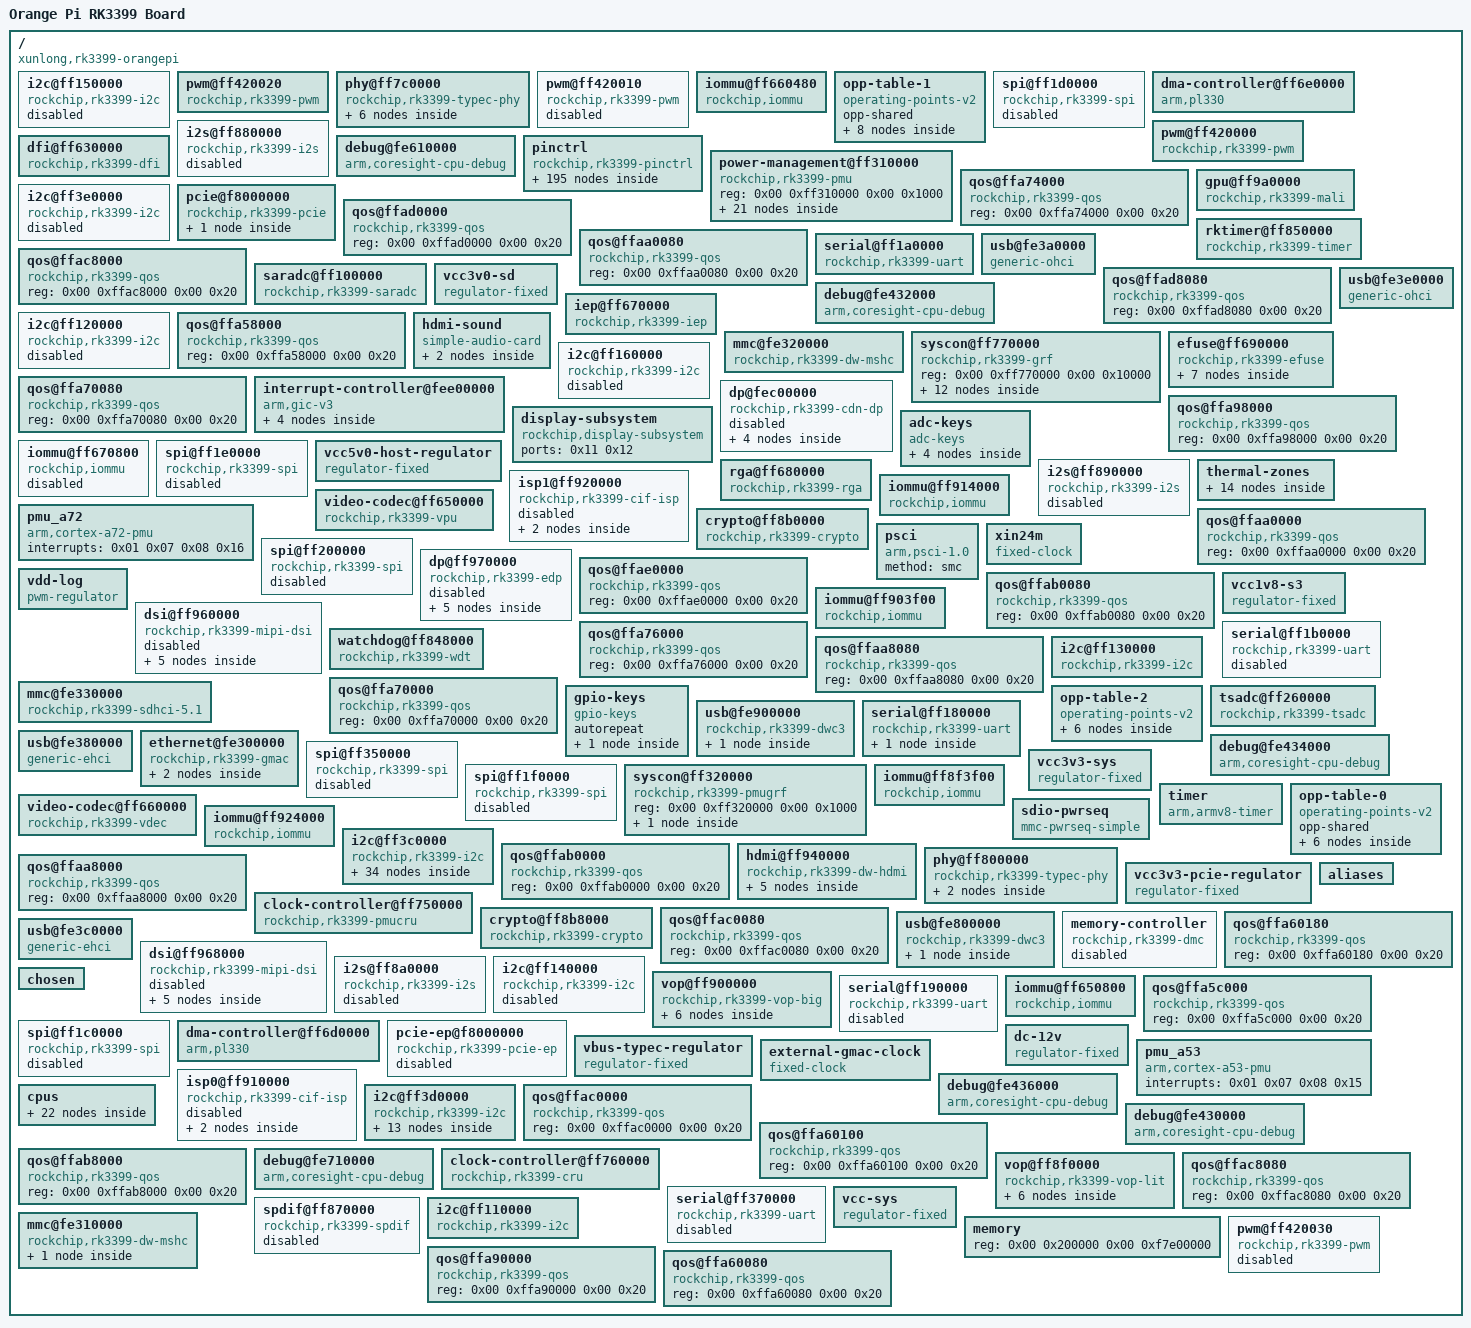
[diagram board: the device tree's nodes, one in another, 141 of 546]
/dts-v1/;

/ {
	#address-cells = <0x02>;
	model = "Orange Pi RK3399 Board";
	serial-number = "e1e9646c4d83d120";
	#size-cells = <0x02>;
	interrupt-parent = <0x01>;
	compatible = "xunlong,rk3399-orangepi\0rockchip,rk3399";

	i2c@ff150000 {
		pinctrl-names = "default";
		#address-cells = <0x01>;
		pinctrl-0 = <0x43>;
		clock-names = "i2c\0pclk";
		assigned-clocks = <0x08 0x45>;
		assigned-clock-rates = <0xbebc200>;
		interrupts = <0x00 0x25 0x04 0x00>;
		clocks = <0x08 0x45 0x08 0x159>;
		#size-cells = <0x00>;
		compatible = "rockchip,rk3399-i2c";
		status = "disabled";
		reg = <0x00 0xff150000 0x00 0x1000>;
		phandle = <0xf0>;
	};

	pwm@ff420020 {
		pinctrl-names = "default";
		pinctrl-0 = <0x9c>;
		clocks = <0x84 0x1e>;
		#pwm-cells = <0x03>;
		compatible = "rockchip,rk3399-pwm\0rockchip,rk3288-pwm";
		status = "okay";
		reg = <0x00 0xff420020 0x00 0x10>;
		phandle = <0xd9>;
	};

	phy@ff7c0000 {
		power-domains = <0x1c 0x08>;
		clock-names = "tcpdcore\0tcpdphy-ref";
		assigned-clocks = <0x08 0x7e>;
		assigned-clock-rates = <0x2faf080>;
		resets = <0x08 0x95 0x08 0x94 0x08 0x14c>;
		clocks = <0x08 0x7e 0x08 0x7d>;
		compatible = "rockchip,rk3399-typec-phy";
		status = "okay";
		rockchip,grf = <0x1d>;
		reg = <0x00 0xff7c0000 0x00 0x40000>;
		phandle = <0x124>;
		reset-names = "uphy\0uphy-pipe\0uphy-tcphy";

		dp-port {
			#phy-cells = <0x00>;
			phandle = <0x3a>;

			port {

				endpoint {
					remote-endpoint = <0xa6>;
					phandle = <0x98>;
				};
			};
		};

		usb3-port {
			#phy-cells = <0x00>;
			phandle = <0x37>;

			port {

				endpoint {
					remote-endpoint = <0xa7>;
					phandle = <0x97>;
				};
			};
		};
	};

	pwm@ff420010 {
		pinctrl-names = "default";
		pinctrl-0 = <0x9b>;
		clocks = <0x84 0x1e>;
		#pwm-cells = <0x03>;
		compatible = "rockchip,rk3399-pwm\0rockchip,rk3288-pwm";
		status = "disabled";
		reg = <0x00 0xff420010 0x00 0x10>;
		phandle = <0x115>;
	};

	iommu@ff660480 {
		power-domains = <0x1c 0x20>;
		clock-names = "aclk\0iface";
		interrupts = <0x00 0x75 0x04 0x00>;
		clocks = <0x08 0xed 0x08 0x1ec>;
		#iommu-cells = <0x00>;
		compatible = "rockchip,iommu";
		reg = <0x00 0xff660480 0x00 0x40 0x00 0xff6604c0 0x00 0x40>;
		phandle = <0x9f>;
	};

	opp-table-1 {
		opp-shared;
		compatible = "operating-points-v2";
		phandle = <0x0f>;

		opp04 {
			opp-microvolt = <0xe7ef0 0xe7ef0 0x1312d0>;
			opp-hz = <0x00 0x47868c00>;
		};

		opp02 {
			opp-microvolt = <0xc96a8 0xc96a8 0x1312d0>;
			opp-hz = <0x00 0x30a32c00>;
		};

		opp00 {
			opp-microvolt = <0xc96a8 0xc96a8 0x1312d0>;
			opp-hz = <0x00 0x18519600>;
			clock-latency-ns = <0x9c40>;
		};

		opp07 {
			opp-microvolt = <0x124f80 0x124f80 0x1312d0>;
			opp-hz = <0x00 0x6b49d200>;
		};

		opp05 {
			opp-microvolt = <0xfa3e8 0xfa3e8 0x1312d0>;
			opp-hz = <0x00 0x54667200>;
		};

		opp03 {
			opp-microvolt = <0xd59f8 0xd59f8 0x1312d0>;
			opp-hz = <0x00 0x3c14dc00>;
		};

		opp01 {
			opp-microvolt = <0xc96a8 0xc96a8 0x1312d0>;
			opp-hz = <0x00 0x23c34600>;
		};

		opp06 {
			opp-microvolt = <0x10c8e0 0x10c8e0 0x1312d0>;
			opp-hz = <0x00 0x5fd82200>;
		};
	};

	spi@ff1d0000 {
		pinctrl-names = "default";
		#address-cells = <0x01>;
		pinctrl-0 = <0x56 0x57 0x58 0x59>;
		clock-names = "spiclk\0apb_pclk";
		interrupts = <0x00 0x35 0x04 0x00>;
		clocks = <0x08 0x48 0x08 0x15c>;
		#size-cells = <0x00>;
		dma-names = "tx\0rx";
		compatible = "rockchip,rk3399-spi\0rockchip,rk3066-spi";
		status = "disabled";
		reg = <0x00 0xff1d0000 0x00 0x1000>;
		phandle = <0xf7>;
		dmas = <0x51 0x0c 0x51 0x0d>;
	};

	dma-controller@ff6e0000 {
		clock-names = "apb_pclk";
		interrupts = <0x00 0x07 0x04 0x00 0x00 0x08 0x04 0x00>;
		clocks = <0x08 0xd4>;
		arm,pl330-periph-burst;
		compatible = "arm,pl330\0arm,primecell";
		reg = <0x00 0xff6e0000 0x00 0x4000>;
		phandle = <0x51>;
		#dma-cells = <0x01>;
	};

	i2s@ff880000 {
		power-domains = <0x1c 0x1c>;
		pinctrl-names = "bclk_on\0bclk_off";
		pinctrl-0 = <0xa9>;
		clock-names = "i2s_clk\0i2s_hclk";
		interrupts = <0x00 0x27 0x04 0x00>;
		clocks = <0x08 0x56 0x08 0x1d4>;
		dma-names = "tx\0rx";
		#sound-dai-cells = <0x00>;
		compatible = "rockchip,rk3399-i2s\0rockchip,rk3066-i2s";
		pinctrl-1 = <0xaa>;
		status = "disabled";
		rockchip,grf = <0x1d>;
		reg = <0x00 0xff880000 0x00 0x1000>;
		phandle = <0x128>;
		dmas = <0x62 0x00 0x62 0x01>;
	};

	pwm@ff420000 {
		pinctrl-names = "default";
		pinctrl-0 = <0x9a>;
		clocks = <0x84 0x1e>;
		#pwm-cells = <0x03>;
		compatible = "rockchip,rk3399-pwm\0rockchip,rk3288-pwm";
		status = "okay";
		reg = <0x00 0xff420000 0x00 0x10>;
		phandle = <0x114>;
	};

	debug@fe610000 {
		clock-names = "apb_pclk";
		clocks = <0x08 0x14c>;
		cpu = <0x06>;
		compatible = "arm,coresight-cpu-debug\0arm,primecell";
		reg = <0x00 0xfe610000 0x00 0x1000>;
	};

	pinctrl {
		#address-cells = <0x02>;
		#size-cells = <0x02>;
		compatible = "rockchip,rk3399-pinctrl";
		rockchip,pmu = <0x13>;
		ranges;
		rockchip,grf = <0x1d>;
		phandle = <0x139>;

		i2c3 {

			i2c3-xfer {
				rockchip,pins = <0x04 0x11 0x01 0xca 0x04 0x10 0x01 0xca>;
				phandle = <0x41>;
			};
		};

		buttons {

			pwr-btn {
				rockchip,pins = <0x00 0x05 0x00 0xcc>;
				phandle = <0xd1>;
			};
		};

		mpu6500 {

			gsensor-int-l {
				rockchip,pins = <0x01 0x16 0x00 0xca>;
				phandle = <0x90>;
			};
		};

		clock {

			clk-32k {
				rockchip,pins = <0x00 0x00 0x02 0xca>;
				phandle = <0x149>;
			};
		};

		spi2 {

			spi2-clk {
				rockchip,pins = <0x02 0x0b 0x01 0xcc>;
				phandle = <0x5a>;
			};

			spi2-cs0 {
				rockchip,pins = <0x02 0x0c 0x01 0xcc>;
				phandle = <0x5d>;
			};

			spi2-tx {
				rockchip,pins = <0x02 0x0a 0x01 0xcc>;
				phandle = <0x5b>;
			};

			spi2-rx {
				rockchip,pins = <0x02 0x09 0x01 0xcc>;
				phandle = <0x5c>;
			};
		};

		pcfg-pull-none-12ma {
			drive-strength = <0x0c>;
			bias-disable;
			phandle = <0xcd>;
		};

		pcfg-pull-up-20ma {
			drive-strength = <0x14>;
			phandle = <0x13e>;
			bias-pull-up;
		};

		gpio@ff720000 {
			gpio-controller;
			interrupts = <0x00 0x0e 0x04 0x00>;
			clocks = <0x84 0x17>;
			compatible = "rockchip,gpio-bank";
			#interrupt-cells = <0x02>;
			reg = <0x00 0xff720000 0x00 0x100>;
			phandle = <0x29>;
			#gpio-cells = <0x02>;
			interrupt-controller;
		};

		pcfg-input-pull-up {
			phandle = <0x147>;
			bias-pull-up;
			input-enable;
		};

		i2s1 {

			i2s1-2ch-bus-bclk-off {
				rockchip,pins = <0x04 0x03 0x00 0xca 0x04 0x04 0x01 0xca 0x04 0x05 0x01 0xca 0x04 0x06 0x01 0xca 0x04 0x07 0x01 0xca>;
				phandle = <0x14f>;
			};

			i2s1-2ch-bus {
				rockchip,pins = <0x04 0x03 0x01 0xca 0x04 0x04 0x01 0xca 0x04 0x05 0x01 0xca 0x04 0x06 0x01 0xca 0x04 0x07 0x01 0xca>;
				phandle = <0xab>;
			};
		};

		i2c1 {

			i2c1-xfer {
				rockchip,pins = <0x04 0x02 0x01 0xca 0x04 0x01 0x01 0xca>;
				phandle = <0x3f>;
			};
		};

		gmac {

			rmii-pins {
				rockchip,pins = <0x03 0x0d 0x01 0xca 0x03 0x0c 0x01 0xcb 0x03 0x0b 0x01 0xca 0x03 0x0a 0x01 0xca 0x03 0x09 0x01 0xca 0x03 0x08 0x01 0xca 0x03 0x07 0x01 0xca 0x03 0x06 0x01 0xca 0x03 0x05 0x01 0xcb 0x03 0x04 0x01 0xcb>;
				phandle = <0x14c>;
			};

			phy-rstb {
				rockchip,pins = <0x03 0x0f 0x00 0xca>;
				phandle = <0x23>;
			};

			phy-intb {
				rockchip,pins = <0x03 0x0a 0x00 0xcc>;
				phandle = <0x22>;
			};

			rgmii-pins {
				rockchip,pins = <0x03 0x11 0x01 0xcb 0x03 0x0e 0x01 0xca 0x03 0x0d 0x01 0xca 0x03 0x0c 0x01 0xcb 0x03 0x0b 0x01 0xca 0x03 0x09 0x01 0xca 0x03 0x08 0x01 0xca 0x03 0x07 0x01 0xca 0x03 0x06 0x01 0xca 0x03 0x05 0x01 0xcb 0x03 0x04 0x01 0xcb 0x03 0x03 0x01 0xca 0x03 0x02 0x01 0xca 0x03 0x01 0x01 0xcb 0x03 0x00 0x01 0xcb>;
				phandle = <0x21>;
			};
		};

		spi0 {

			spi0-tx {
				rockchip,pins = <0x03 0x05 0x02 0xcc>;
				phandle = <0x53>;
			};

			spi0-rx {
				rockchip,pins = <0x03 0x04 0x02 0xcc>;
				phandle = <0x54>;
			};

			spi0-cs1 {
				rockchip,pins = <0x03 0x08 0x02 0xcc>;
				phandle = <0x15c>;
			};

			spi0-clk {
				rockchip,pins = <0x03 0x06 0x02 0xcc>;
				phandle = <0x52>;
			};

			spi0-cs0 {
				rockchip,pins = <0x03 0x07 0x02 0xcc>;
				phandle = <0x55>;
			};
		};

		pcfg-pull-down-4ma {
			drive-strength = <0x04>;
			bias-pull-down;
			phandle = <0x13f>;
		};

		wifi {

			wifi-host-wake-l {
				rockchip,pins = <0x00 0x03 0x00 0xca>;
				phandle = <0x2a>;
			};
		};

		cm32181 {

			light-int-l {
				rockchip,pins = <0x04 0x18 0x00 0xca>;
				phandle = <0x93>;
			};
		};

		pcfg-pull-down {
			bias-pull-down;
			phandle = <0xcf>;
		};

		uart4 {

			uart4-xfer {
				rockchip,pins = <0x01 0x07 0x01 0xcc 0x01 0x08 0x01 0xca>;
				phandle = <0x89>;
			};
		};

		pcfg-pull-none-18ma {
			drive-strength = <0x12>;
			bias-disable;
			phandle = <0x13a>;
		};

		i2c8 {

			i2c8-xfer {
				rockchip,pins = <0x01 0x15 0x01 0xca 0x01 0x14 0x01 0xca>;
				phandle = <0x99>;
			};
		};

		pcfg-input-pull-down {
			bias-pull-down;
			phandle = <0x148>;
			input-enable;
		};

		pcfg-pull-none-20ma {
			drive-strength = <0x14>;
			bias-disable;
			phandle = <0x13b>;
		};

		gpio@ff730000 {
			gpio-controller;
			interrupts = <0x00 0x0f 0x04 0x00>;
			clocks = <0x84 0x18>;
			compatible = "rockchip,gpio-bank";
			#interrupt-cells = <0x02>;
			reg = <0x00 0xff730000 0x00 0x100>;
			phandle = <0x8b>;
			#gpio-cells = <0x02>;
			interrupt-controller;
		};

		i2c6 {

			i2c6-xfer {
				rockchip,pins = <0x02 0x0a 0x02 0xca 0x02 0x09 0x02 0xca>;
				phandle = <0x43>;
			};
		};

		uarthdcp {

			uarthdcp-xfer {
				rockchip,pins = <0x04 0x15 0x02 0xcc 0x04 0x16 0x02 0xca>;
				phandle = <0x164>;
			};
		};

		pwm1 {

			pwm1-pin {
				rockchip,pins = <0x04 0x16 0x01 0xca>;
				phandle = <0x9b>;
			};

			pwm1-pin-pull-down {
				rockchip,pins = <0x04 0x16 0x01 0xcf>;
				phandle = <0x168>;
			};
		};

		uart2b {

			uart2b-xfer {
				rockchip,pins = <0x04 0x10 0x02 0xcc 0x04 0x11 0x02 0xca>;
				phandle = <0x161>;
			};
		};

		edp {

			edp-hpd {
				rockchip,pins = <0x04 0x17 0x02 0xca>;
				phandle = <0xc5>;
			};
		};

		spi5 {

			spi5-cs0 {
				rockchip,pins = <0x02 0x17 0x02 0xcc>;
				phandle = <0x66>;
			};

			spi5-tx {
				rockchip,pins = <0x02 0x15 0x02 0xcc>;
				phandle = <0x64>;
			};

			spi5-rx {
				rockchip,pins = <0x02 0x14 0x02 0xcc>;
				phandle = <0x65>;
			};

			spi5-clk {
				rockchip,pins = <0x02 0x16 0x02 0xcc>;
				phandle = <0x63>;
			};
		};

		tsadc {

			otp-pin {
				rockchip,pins = <0x01 0x06 0x00 0xca>;
				phandle = <0x6c>;
			};

			otp-out {
				rockchip,pins = <0x01 0x06 0x01 0xca>;
				phandle = <0x6d>;
			};
		};

		uart0 {

			uart0-cts {
				rockchip,pins = <0x02 0x12 0x01 0xca>;
				phandle = <0x46>;
			};

			uart0-rts {
				rockchip,pins = <0x02 0x13 0x01 0xca>;
				phandle = <0x47>;
			};

			uart0-xfer {
				rockchip,pins = <0x02 0x10 0x01 0xcc 0x02 0x11 0x01 0xca>;
				phandle = <0x45>;
			};
		};

		i2c4 {

			i2c4-xfer {
				rockchip,pins = <0x01 0x0c 0x01 0xca 0x01 0x0b 0x01 0xca>;
				phandle = <0x8f>;
			};
		};

		pcfg-pull-down-12ma {
			drive-strength = <0x0c>;
			bias-pull-down;
			phandle = <0x141>;
		};

		spdif {

			spdif-bus-1 {
				rockchip,pins = <0x03 0x10 0x03 0xca>;
				phandle = <0x15b>;
			};

			spdif-bus {
				rockchip,pins = <0x04 0x15 0x01 0xca>;
				phandle = <0xa8>;
			};
		};

		pcfg-output-high {
			output-high;
			phandle = <0x144>;
		};

		pcie {

			pci-clkreqn-cpm {
				rockchip,pins = <0x02 0x1a 0x00 0xca>;
				phandle = <0x16d>;
			};

			pci-clkreqnb-cpm {
				rockchip,pins = <0x04 0x18 0x00 0xca>;
				phandle = <0x1b>;
			};

			pcie-drv {
				rockchip,pins = <0x00 0x02 0x00 0xca>;
				phandle = <0xd4>;
			};
		};

		sd {

			sdmmc0-pwr-h {
				rockchip,pins = <0x00 0x01 0x00 0xca>;
				phandle = <0xd3>;
			};
		};

		pcfg-pull-up {
			phandle = <0xcc>;
			bias-pull-up;
		};

		spi3 {

			spi3-tx {
				rockchip,pins = <0x01 0x10 0x01 0xcc>;
				phandle = <0x86>;
			};

			spi3-rx {
				rockchip,pins = <0x01 0x0f 0x01 0xcc>;
				phandle = <0x87>;
			};

			spi3-clk {
				rockchip,pins = <0x01 0x11 0x01 0xcc>;
				phandle = <0x85>;
			};

			spi3-cs0 {
				rockchip,pins = <0x01 0x12 0x01 0xcc>;
				phandle = <0x88>;
			};
		};

		fusb302 {

			chg-cc-int-l {
				rockchip,pins = <0x01 0x02 0x00 0xcc>;
				phandle = <0x94>;
			};
		};

		pwm3a {

			pwm3a-pin {
				rockchip,pins = <0x00 0x06 0x01 0xca>;
				phandle = <0x9d>;
			};
		};

		sdio0 {

			sdio0-clk {
				rockchip,pins = <0x02 0x19 0x01 0xca>;
				phandle = <0x28>;
			};

			sdio0-wp {
				rockchip,pins = <0x00 0x03 0x01 0xcc>;
				phandle = <0x154>;
			};

			sdio0-bus4 {
				rockchip,pins = <0x02 0x14 0x01 0xcc 0x02 0x15 0x01 0xcc 0x02 0x16 0x01 0xcc 0x02 0x17 0x01 0xcc>;
				phandle = <0x26>;
			};

			sdmmc-pwr {
				rockchip,pins = <0x00 0x01 0x01 0xcc>;
				phandle = <0x156>;
			};

			sdio0-bkpwr {
				rockchip,pins = <0x02 0x1c 0x01 0xcc>;
				phandle = <0x153>;
			};

			sdio0-cd {
				rockchip,pins = <0x02 0x1a 0x01 0xcc>;
				phandle = <0x151>;
			};

			sdio0-pwr {
				rockchip,pins = <0x02 0x1b 0x01 0xcc>;
				phandle = <0x152>;
			};

			sdio0-int {
				rockchip,pins = <0x00 0x04 0x01 0xcc>;
				phandle = <0x155>;
			};

			sdio0-bus1 {
				rockchip,pins = <0x02 0x14 0x01 0xcc>;
				phandle = <0x150>;
			};

			sdio0-cmd {
				rockchip,pins = <0x02 0x18 0x01 0xcc>;
				phandle = <0x27>;
			};
		};

		pcfg-pull-up-2ma {
			drive-strength = <0x02>;
			phandle = <0x13c>;
			bias-pull-up;
		};

		i2c2 {

			i2c2-xfer {
				rockchip,pins = <0x02 0x01 0x02 0xcd 0x02 0x00 0x02 0xcd>;
				phandle = <0x40>;
			};
		};

		lsm6ds3 {

			gyr-int-l {
				rockchip,pins = <0x01 0x18 0x00 0xca>;
				phandle = <0x91>;
			};
		};

		pmic {

			gpu-sleep {
				rockchip,pins = <0x01 0x0e 0x00 0xcf>;
				phandle = <0x8e>;
			};

			cpu-b-sleep {
				rockchip,pins = <0x01 0x11 0x00 0xcf>;
				phandle = <0x8d>;
			};

			pmic-int-l {
				rockchip,pins = <0x01 0x15 0x00 0xcc>;
				phandle = <0x8c>;
			};
		};

		pcfg-input-enable {
			phandle = <0x146>;
			input-enable;
		};

		pcfg-pull-none {
			bias-disable;
			phandle = <0xca>;
		};

		spi1 {

			spi1-cs0 {
				rockchip,pins = <0x01 0x0a 0x02 0xcc>;
				phandle = <0x59>;
			};

			spi1-clk {
				rockchip,pins = <0x01 0x09 0x02 0xcc>;
				phandle = <0x56>;
			};

			spi1-tx {
				rockchip,pins = <0x01 0x08 0x02 0xcc>;
				phandle = <0x57>;
			};

			spi1-rx {
				rockchip,pins = <0x01 0x07 0x02 0xcc>;
				phandle = <0x58>;
			};
		};

		sdio-pwrseq {

			wifi-reg-on-h {
				rockchip,pins = <0x00 0x0a 0x00 0xca>;
				phandle = <0xd2>;
			};
		};

		bluetooth {

			bt-wake-l {
				rockchip,pins = <0x02 0x1a 0x00 0xca>;
				phandle = <0x4a>;
			};

			bt-host-wake-l {
				rockchip,pins = <0x00 0x04 0x00 0xca>;
				phandle = <0x49>;
			};

			bt-enable-h {
				rockchip,pins = <0x00 0x09 0x00 0xca>;
				phandle = <0x4b>;
			};
		};

		gpio@ff780000 {
			gpio-controller;
			interrupts = <0x00 0x10 0x04 0x00>;
			clocks = <0x08 0x150>;
			compatible = "rockchip,gpio-bank";
			#interrupt-cells = <0x02>;
			reg = <0x00 0xff780000 0x00 0x100>;
			phandle = <0x1a>;
			#gpio-cells = <0x02>;
			interrupt-controller;
		};

		pcfg-pull-down-18ma {
			drive-strength = <0x12>;
			bias-pull-down;
			phandle = <0x142>;
		};

		sdmmc {

			sdmmc-wp {
				rockchip,pins = <0x00 0x08 0x01 0xce>;
				phandle = <0x158>;
			};

			sdmmc-bus1 {
				rockchip,pins = <0x04 0x08 0x01 0xce>;
				phandle = <0x157>;
			};

			sdmmc-cd {
				rockchip,pins = <0x00 0x07 0x01 0xcc>;
				phandle = <0x2d>;
			};

			sdmmc-bus4 {
				rockchip,pins = <0x04 0x08 0x01 0xce 0x04 0x09 0x01 0xce 0x04 0x0a 0x01 0xce 0x04 0x0b 0x01 0xce>;
				phandle = <0x2e>;
			};

			sdmmc-cmd {
				rockchip,pins = <0x04 0x0d 0x01 0xce>;
				phandle = <0x2c>;
			};

			sdmmc-clk {
				rockchip,pins = <0x04 0x0c 0x01 0xcd>;
				phandle = <0x2b>;
			};
		};

		i2s0 {

			i2s0-8ch-bus {
				rockchip,pins = <0x03 0x18 0x01 0xca 0x03 0x19 0x01 0xca 0x03 0x1a 0x01 0xca 0x03 0x1b 0x01 0xca 0x03 0x1c 0x01 0xca 0x03 0x1d 0x01 0xca 0x03 0x1e 0x01 0xca 0x03 0x1f 0x01 0xca 0x04 0x00 0x01 0xca>;
				phandle = <0xa9>;
			};

			i2s0-8ch-bus-bclk-off {
				rockchip,pins = <0x03 0x18 0x00 0xca 0x03 0x19 0x01 0xca 0x03 0x1a 0x01 0xca 0x03 0x1b 0x01 0xca 0x03 0x1c 0x01 0xca 0x03 0x1d 0x01 0xca 0x03 0x1e 0x01 0xca 0x03 0x1f 0x01 0xca 0x04 0x00 0x01 0xca>;
				phandle = <0xaa>;
			};

			i2s0-2ch-bus-bclk-off {
				rockchip,pins = <0x03 0x18 0x00 0xca 0x03 0x19 0x01 0xca 0x03 0x1a 0x01 0xca 0x03 0x1b 0x01 0xca 0x03 0x1f 0x01 0xca 0x04 0x00 0x01 0xca>;
				phandle = <0x14e>;
			};

			i2s0-2ch-bus {
				rockchip,pins = <0x03 0x18 0x01 0xca 0x03 0x19 0x01 0xca 0x03 0x1a 0x01 0xca 0x03 0x1b 0x01 0xca 0x03 0x1f 0x01 0xca 0x04 0x00 0x01 0xca>;
				phandle = <0x14d>;
			};
		};

		i2c0 {

			i2c0-xfer {
				rockchip,pins = <0x01 0x0f 0x02 0xca 0x01 0x10 0x02 0xca>;
				phandle = <0x8a>;
			};
		};

		suspend {

			ap-pwroff {
				rockchip,pins = <0x01 0x05 0x01 0xca>;
				phandle = <0x159>;
			};

			ddrio-pwroff {
				rockchip,pins = <0x00 0x01 0x01 0xca>;
				phandle = <0x15a>;
			};
		};

		usb2 {

			vcc5v0-typec-en {
				rockchip,pins = <0x01 0x03 0x00 0xca>;
				phandle = <0xd7>;
			};

			vcc5v0-host-en {
				rockchip,pins = <0x04 0x19 0x00 0xca>;
				phandle = <0xd6>;
			};
		};

		testclk {

			test-clkout2 {
				rockchip,pins = <0x00 0x08 0x03 0xca>;
				phandle = <0x15f>;
			};

			test-clkout0 {
				rockchip,pins = <0x00 0x00 0x01 0xca>;
				phandle = <0x15d>;
			};

			test-clkout1 {
				rockchip,pins = <0x02 0x19 0x02 0xca>;
				phandle = <0x15e>;
			};
		};

		pcfg-pull-up-8ma {
			drive-strength = <0x08>;
			phandle = <0xce>;
			bias-pull-up;
		};

		pcfg-pull-down-20ma {
			drive-strength = <0x14>;
			bias-pull-down;
			phandle = <0x143>;
		};

		pcfg-pull-none-13ma {
			drive-strength = <0x0d>;
			bias-disable;
			phandle = <0xcb>;
		};

		uart3 {

			uart3-cts {
				rockchip,pins = <0x03 0x10 0x02 0xca>;
				phandle = <0x162>;
			};

			uart3-rts {
				rockchip,pins = <0x03 0x11 0x02 0xca>;
				phandle = <0x163>;
			};

			uart3-xfer {
				rockchip,pins = <0x03 0x0e 0x02 0xcc 0x03 0x0f 0x02 0xca>;
				phandle = <0x50>;
			};
		};

		pcfg-output-low {
			phandle = <0x145>;
			output-low;
		};

		i2c7 {

			i2c7-xfer {
				rockchip,pins = <0x02 0x08 0x02 0xca 0x02 0x07 0x02 0xca>;
				phandle = <0x44>;
			};
		};

		pwm2 {

			pwm2-pin {
				rockchip,pins = <0x01 0x13 0x01 0xca>;
				phandle = <0x9c>;
			};

			pwm2-pin-pull-down {
				rockchip,pins = <0x01 0x13 0x01 0xcf>;
				phandle = <0x169>;
			};
		};

		uart2c {

			uart2c-xfer {
				rockchip,pins = <0x04 0x13 0x01 0xcc 0x04 0x14 0x01 0xca>;
				phandle = <0x4f>;
			};
		};

		uart1 {

			uart1-xfer {
				rockchip,pins = <0x03 0x0c 0x02 0xcc 0x03 0x0d 0x02 0xca>;
				phandle = <0x4e>;
			};
		};

		hdmi {

			hdmi-i2c-xfer {
				rockchip,pins = <0x04 0x11 0x03 0xca 0x04 0x10 0x03 0xca>;
				phandle = <0x16b>;
			};

			hdmi-cec {
				rockchip,pins = <0x04 0x17 0x01 0xca>;
				phandle = <0x16c>;
			};
		};

		gpio@ff790000 {
			gpio-controller;
			interrupts = <0x00 0x12 0x04 0x00>;
			clocks = <0x08 0x152>;
			compatible = "rockchip,gpio-bank";
			#interrupt-cells = <0x02>;
			reg = <0x00 0xff790000 0x00 0x100>;
			phandle = <0x92>;
			#gpio-cells = <0x02>;
			interrupt-controller;
		};

		i2c5 {

			i2c5-xfer {
				rockchip,pins = <0x03 0x0b 0x02 0xca 0x03 0x0a 0x02 0xca>;
				phandle = <0x42>;
			};
		};

		gpio@ff788000 {
			gpio-controller;
			interrupts = <0x00 0x11 0x04 0x00>;
			clocks = <0x08 0x151>;
			compatible = "rockchip,gpio-bank";
			#interrupt-cells = <0x02>;
			reg = <0x00 0xff788000 0x00 0x100>;
			phandle = <0x24>;
			#gpio-cells = <0x02>;
			interrupt-controller;
		};

		pwm0 {

			pwm0-pin-pull-down {
				rockchip,pins = <0x04 0x12 0x01 0xcf>;
				phandle = <0x165>;
			};

			vop1-pwm-pin {
				rockchip,pins = <0x04 0x12 0x03 0xca>;
				phandle = <0x167>;
			};

			vop0-pwm-pin {
				rockchip,pins = <0x04 0x12 0x02 0xca>;
				phandle = <0x166>;
			};

			pwm0-pin {
				rockchip,pins = <0x04 0x12 0x01 0xca>;
				phandle = <0x9a>;
			};
		};

		cif {

			cif-clkin {
				rockchip,pins = <0x02 0x0a 0x03 0xca>;
				phandle = <0x14a>;
			};

			cif-clkouta {
				rockchip,pins = <0x02 0x0b 0x03 0xca>;
				phandle = <0x14b>;
			};
		};

		uart2a {

			uart2a-xfer {
				rockchip,pins = <0x04 0x08 0x02 0xcc 0x04 0x09 0x02 0xca>;
				phandle = <0x160>;
			};
		};

		spi4 {

			spi4-clk {
				rockchip,pins = <0x03 0x02 0x02 0xcc>;
				phandle = <0x5e>;
			};

			spi4-tx {
				rockchip,pins = <0x03 0x01 0x02 0xcc>;
				phandle = <0x5f>;
			};

			spi4-rx {
				rockchip,pins = <0x03 0x00 0x02 0xcc>;
				phandle = <0x60>;
			};

			spi4-cs0 {
				rockchip,pins = <0x03 0x03 0x02 0xcc>;
				phandle = <0x61>;
			};
		};

		pcfg-pull-down-8ma {
			drive-strength = <0x08>;
			bias-pull-down;
			phandle = <0x140>;
		};

		pwm3b {

			pwm3b-pin {
				rockchip,pins = <0x01 0x0e 0x01 0xca>;
				phandle = <0x16a>;
			};
		};

		pcfg-pull-up-18ma {
			drive-strength = <0x12>;
			phandle = <0x13d>;
			bias-pull-up;
		};
	};

	power-management@ff310000 {
		compatible = "rockchip,rk3399-pmu\0syscon\0simple-mfd";
		reg = <0x00 0xff310000 0x00 0x1000>;
		phandle = <0x104>;

		power-controller {
			#address-cells = <0x01>;
			#size-cells = <0x00>;
			#power-domain-cells = <0x01>;
			compatible = "rockchip,rk3399-power-controller";
			phandle = <0x1c>;

			power-domain@9 {
				clocks = <0x08 0x80 0x08 0x7f>;
				#power-domain-cells = <0x00>;
				reg = <0x09>;
			};

			power-domain@27 {
				clocks = <0x08 0x1ce 0x08 0x4c>;
				#power-domain-cells = <0x00>;
				reg = <0x1b>;
				pm_qos = <0x77>;
			};

			power-domain@35 {
				clocks = <0x08 0xd0>;
				#power-domain-cells = <0x00>;
				reg = <0x23>;
				pm_qos = <0x74>;
			};

			power-domain@25 {
				clocks = <0x08 0x16c>;
				#power-domain-cells = <0x00>;
				reg = <0x19>;
			};

			power-domain@15 {
				#address-cells = <0x01>;
				#size-cells = <0x00>;
				#power-domain-cells = <0x01>;
				reg = <0x0f>;

				power-domain@19 {
					clocks = <0x08 0xe5 0x08 0x1df>;
					#power-domain-cells = <0x00>;
					reg = <0x13>;
					pm_qos = <0x7c 0x7d>;
				};

				power-domain@21 {
					clocks = <0x08 0xde 0x08 0x1e7 0x08 0x172>;
					#power-domain-cells = <0x00>;
					reg = <0x15>;
					pm_qos = <0x7b>;
				};

				power-domain@16 {
					#address-cells = <0x01>;
					#size-cells = <0x00>;
					#power-domain-cells = <0x01>;
					reg = <0x10>;

					power-domain@17 {
						clocks = <0x08 0xd9 0x08 0x1d9>;
						#power-domain-cells = <0x00>;
						reg = <0x11>;
						pm_qos = <0x80 0x81>;
					};

					power-domain@18 {
						clocks = <0x08 0xdb 0x08 0x1db>;
						#power-domain-cells = <0x00>;
						reg = <0x12>;
						pm_qos = <0x82>;
					};
				};

				power-domain@20 {
					clocks = <0x08 0xe6 0x08 0x1e0>;
					#power-domain-cells = <0x00>;
					reg = <0x14>;
					pm_qos = <0x7e 0x7f>;
				};
			};

			power-domain@33 {
				clocks = <0x08 0xdc 0x08 0x1e5>;
				#power-domain-cells = <0x00>;
				reg = <0x21>;
				pm_qos = <0x6f 0x70>;
			};

			power-domain@23 {
				clocks = <0x08 0xf0>;
				#power-domain-cells = <0x00>;
				reg = <0x17>;
				pm_qos = <0x75>;
			};

			power-domain@31 {
				clocks = <0x08 0xeb 0x08 0x1ea>;
				#power-domain-cells = <0x00>;
				reg = <0x1f>;
				pm_qos = <0x71>;
			};

			power-domain@28 {
				clocks = <0x08 0x1ee>;
				#power-domain-cells = <0x00>;
				reg = <0x1c>;
				pm_qos = <0x78>;
			};

			power-domain@8 {
				clocks = <0x08 0x7e 0x08 0x7d>;
				#power-domain-cells = <0x00>;
				reg = <0x08>;
			};

			power-domain@34 {
				clocks = <0x08 0xe1 0x08 0x1dd>;
				#power-domain-cells = <0x00>;
				reg = <0x22>;
				pm_qos = <0x6e>;
			};

			power-domain@24 {
				clocks = <0x08 0xf4>;
				#power-domain-cells = <0x00>;
				reg = <0x18>;
				pm_qos = <0x79 0x7a>;
			};

			power-domain@32 {
				clocks = <0x08 0xed 0x08 0x1ec 0x08 0x9f 0x08 0x9e>;
				#power-domain-cells = <0x00>;
				reg = <0x20>;
				pm_qos = <0x72 0x73>;
			};

			power-domain@22 {
				clocks = <0x08 0xd5 0x08 0x166>;
				#power-domain-cells = <0x00>;
				reg = <0x16>;
				pm_qos = <0x76>;
			};
		};
	};

	qos@ffa74000 {
		compatible = "rockchip,rk3399-qos\0syscon";
		reg = <0x00 0xffa74000 0x00 0x20>;
		phandle = <0x77>;
	};

	gpu@ff9a0000 {
		power-domains = <0x1c 0x23>;
		mali-supply = <0xc9>;
		interrupts = <0x00 0x14 0x04 0x00 0x00 0x15 0x04 0x00 0x00 0x13 0x04 0x00>;
		clocks = <0x08 0xd0>;
		compatible = "rockchip,rk3399-mali\0arm,mali-t860";
		dynamic-power-coefficient = <0xa50>;
		status = "okay";
		interrupt-names = "job\0mmu\0gpu";
		reg = <0x00 0xff9a0000 0x00 0x10000>;
		phandle = <0x6b>;
		operating-points-v2 = <0xc8>;
		#cooling-cells = <0x02>;
	};

	dfi@ff630000 {
		clock-names = "pclk_ddr_mon";
		interrupts = <0x00 0x83 0x04 0x00>;
		clocks = <0x08 0x179>;
		compatible = "rockchip,rk3399-dfi";
		rockchip,pmu = <0x13>;
		reg = <0x00 0xff630000 0x00 0x4000>;
		phandle = <0x14>;
	};

	i2c@ff3e0000 {
		pinctrl-names = "default";
		#address-cells = <0x01>;
		pinctrl-0 = <0x99>;
		clock-names = "i2c\0pclk";
		assigned-clocks = <0x84 0x0b>;
		assigned-clock-rates = <0xbebc200>;
		interrupts = <0x00 0x3a 0x04 0x00>;
		clocks = <0x84 0x0b 0x84 0x1d>;
		#size-cells = <0x00>;
		compatible = "rockchip,rk3399-i2c";
		status = "disabled";
		reg = <0x00 0xff3e0000 0x00 0x1000>;
		phandle = <0x113>;
	};

	pcie@f8000000 {
		#address-cells = <0x03>;
		phy-names = "pcie-phy-0\0pcie-phy-1\0pcie-phy-2\0pcie-phy-3";
		bus-range = <0x00 0x1f>;
		clock-names = "aclk\0aclk-perf\0hclk\0pm";
		reg-names = "axi-base\0apb-base";
		ep-gpios = <0x1a 0x04 0x00>;
		resets = <0x08 0x82 0x08 0x83 0x08 0x84 0x08 0x85 0x08 0x86 0x08 0x81 0x08 0x80>;
		interrupts = <0x00 0x31 0x04 0x00 0x00 0x32 0x04 0x00 0x00 0x33 0x04 0x00>;
		clocks = <0x08 0xc5 0x08 0xc4 0x08 0x147 0x08 0xa0>;
		interrupt-map = <0x00 0x00 0x00 0x01 0x17 0x00 0x00 0x00 0x00 0x02 0x17 0x01 0x00 0x00 0x00 0x03 0x17 0x02 0x00 0x00 0x00 0x04 0x17 0x03>;
		#size-cells = <0x02>;
		aspm-no-l0s;
		max-link-speed = <0x01>;
		device_type = "pci";
		interrupt-map-mask = <0x00 0x00 0x00 0x07>;
		num-lanes = <0x04>;
		compatible = "rockchip,rk3399-pcie";
		ranges = <0x82000000 0x00 0xfa000000 0x00 0xfa000000 0x00 0x1e00000 0x81000000 0x00 0xfbe00000 0x00 0xfbe00000 0x00 0x100000>;
		msi-map = <0x00 0x18 0x00 0x1000>;
		#interrupt-cells = <0x01>;
		status = "okay";
		interrupt-names = "sys\0legacy\0client";
		phys = <0x19 0x00 0x19 0x01 0x19 0x02 0x19 0x03>;
		reg = <0x00 0xf8000000 0x00 0x2000000 0x00 0xfd000000 0x00 0x1000000>;
		phandle = <0xdb>;
		reset-names = "core\0mgmt\0mgmt-sticky\0pipe\0pm\0pclk\0aclk";

		interrupt-controller {
			#address-cells = <0x00>;
			#interrupt-cells = <0x01>;
			phandle = <0x17>;
			interrupt-controller;
		};
	};

	qos@ffad0000 {
		compatible = "rockchip,rk3399-qos\0syscon";
		reg = <0x00 0xffad0000 0x00 0x20>;
		phandle = <0x82>;
	};

	rktimer@ff850000 {
		clock-names = "pclk\0timer";
		interrupts = <0x00 0x51 0x04 0x00>;
		clocks = <0x08 0x168 0x08 0x5a>;
		compatible = "rockchip,rk3399-timer";
		reg = <0x00 0xff850000 0x00 0x1000>;
		phandle = <0x126>;
	};

	qos@ffaa0080 {
		compatible = "rockchip,rk3399-qos\0syscon";
		reg = <0x00 0xffaa0080 0x00 0x20>;
		phandle = <0x7d>;
	};

	serial@ff1a0000 {
		reg-io-width = <0x04>;
		pinctrl-names = "default";
		pinctrl-0 = <0x4f>;
		clock-names = "baudclk\0apb_pclk";
		interrupts = <0x00 0x64 0x04 0x00>;
		clocks = <0x08 0x53 0x08 0x162>;
		compatible = "rockchip,rk3399-uart\0snps,dw-apb-uart";
		status = "okay";
		reg = <0x00 0xff1a0000 0x00 0x100>;
		phandle = <0xf4>;
		reg-shift = <0x02>;
	};

	qos@ffac8000 {
		compatible = "rockchip,rk3399-qos\0syscon";
		reg = <0x00 0xffac8000 0x00 0x20>;
		phandle = <0x80>;
	};

	usb@fe3a0000 {
		phy-names = "usb";
		interrupts = <0x00 0x1c 0x04 0x00>;
		clocks = <0x08 0x1c8 0x08 0x1c9 0x32>;
		compatible = "generic-ohci";
		status = "okay";
		phys = <0x33>;
		reg = <0x00 0xfe3a0000 0x00 0x20000>;
		phandle = <0xe2>;
	};

	saradc@ff100000 {
		vref-supply = <0x3e>;
		clock-names = "saradc\0apb_pclk";
		resets = <0x08 0xd4>;
		interrupts = <0x00 0x3e 0x04 0x00>;
		clocks = <0x08 0x50 0x08 0x165>;
		#io-channel-cells = <0x01>;
		compatible = "rockchip,rk3399-saradc";
		status = "okay";
		reg = <0x00 0xff100000 0x00 0x100>;
		phandle = <0xd0>;
		reset-names = "saradc-apb";
	};

	vcc3v0-sd {
		regulator-max-microvolt = <0x2dc6c0>;
		pinctrl-names = "default";
		regulator-boot-on;
		gpio = <0x29 0x01 0x00>;
		pinctrl-0 = <0xd3>;
		enable-active-high;
		regulator-min-microvolt = <0x2dc6c0>;
		regulator-name = "vcc3v0_sd";
		compatible = "regulator-fixed";
		phandle = <0x2f>;
		vin-supply = <0x4c>;
	};

	qos@ffad8080 {
		compatible = "rockchip,rk3399-qos\0syscon";
		reg = <0x00 0xffad8080 0x00 0x20>;
		phandle = <0x103>;
	};

	usb@fe3e0000 {
		phy-names = "usb";
		interrupts = <0x00 0x20 0x04 0x00>;
		clocks = <0x08 0x1ca 0x08 0x1cb 0x34>;
		compatible = "generic-ohci";
		status = "okay";
		phys = <0x35>;
		reg = <0x00 0xfe3e0000 0x00 0x20000>;
		phandle = <0xe4>;
	};

	debug@fe432000 {
		clock-names = "apb_pclk";
		clocks = <0x08 0x14d>;
		cpu = <0x03>;
		compatible = "arm,coresight-cpu-debug\0arm,primecell";
		reg = <0x00 0xfe432000 0x00 0x1000>;
	};

	iep@ff670000 {
		power-domains = <0x1c 0x22>;
		iommus = <0xa0>;
		clock-names = "axi\0ahb";
		interrupts = <0x00 0x2a 0x04 0x00>;
		clocks = <0x08 0xe1 0x08 0x1dd>;
		compatible = "rockchip,rk3399-iep\0rockchip,rk3228-iep";
		interrupt-names = "iep";
		reg = <0x00 0xff670000 0x00 0x800>;
		phandle = <0x119>;
	};

	i2c@ff120000 {
		pinctrl-names = "default";
		#address-cells = <0x01>;
		pinctrl-0 = <0x40>;
		clock-names = "i2c\0pclk";
		assigned-clocks = <0x08 0x42>;
		assigned-clock-rates = <0xbebc200>;
		interrupts = <0x00 0x23 0x04 0x00>;
		clocks = <0x08 0x42 0x08 0x156>;
		#size-cells = <0x00>;
		compatible = "rockchip,rk3399-i2c";
		status = "disabled";
		reg = <0x00 0xff120000 0x00 0x1000>;
		phandle = <0xee>;
	};

	qos@ffa58000 {
		compatible = "rockchip,rk3399-qos\0syscon";
		reg = <0x00 0xffa58000 0x00 0x20>;
		phandle = <0x75>;
	};

	mmc@fe320000 {
		power-domains = <0x1c 0x1b>;
		fifo-depth = <0x100>;
		pinctrl-names = "default";
		pinctrl-0 = <0x2b 0x2c 0x2d 0x2e>;
		clock-names = "biu\0ciu\0ciu-drive\0ciu-sample";
		cap-sd-highspeed;
		vqmmc-supply = <0x30>;
		assigned-clocks = <0x08 0x1cd>;
		bus-width = <0x04>;
		assigned-clock-rates = <0xbebc200>;
		resets = <0x08 0x7a>;
		interrupts = <0x00 0x41 0x04 0x00>;
		clocks = <0x08 0x1ce 0x08 0x4c 0x08 0x9a 0x08 0x9b>;
		vmmc-supply = <0x2f>;
		clock-frequency = <0x8f0d180>;
		compatible = "rockchip,rk3399-dw-mshc\0rockchip,rk3288-dw-mshc";
		status = "okay";
		disable-wp;
		reg = <0x00 0xfe320000 0x00 0x4000>;
		phandle = <0xe0>;
		max-frequency = <0x8f0d180>;
		cap-mmc-highspeed;
		reset-names = "reset";
		cd-gpios = <0x29 0x07 0x01>;
	};

	hdmi-sound {
		simple-audio-card,name = "hdmi-sound";
		simple-audio-card,format = "i2s";
		compatible = "simple-audio-card";
		status = "okay";
		phandle = <0x12e>;
		simple-audio-card,mclk-fs = <0x100>;

		simple-audio-card,cpu {
			sound-dai = <0xbc>;
		};

		simple-audio-card,codec {
			sound-dai = <0xbd>;
		};
	};

	syscon@ff770000 {
		#address-cells = <0x01>;
		#size-cells = <0x01>;
		compatible = "rockchip,rk3399-grf\0syscon\0simple-mfd";
		reg = <0x00 0xff770000 0x00 0x10000>;
		phandle = <0x1d>;

		mipi-dphy-rx0 {
			power-domains = <0x1c 0x0f>;
			clock-names = "dphy-ref\0dphy-cfg\0grf";
			clocks = <0x08 0x77 0x08 0xa5 0x08 0x16f>;
			#phy-cells = <0x00>;
			compatible = "rockchip,rk3399-mipi-dphy-rx0";
			status = "disabled";
			phandle = <0xb9>;
		};

		pcie-phy {
			clock-names = "refclk";
			assigned-clocks = <0x08 0x8a>;
			assigned-clock-parents = <0x08 0xa7>;
			assigned-clock-rates = <0x5f5e100>;
			resets = <0x08 0x87>;
			clocks = <0x08 0x8a>;
			#phy-cells = <0x01>;
			compatible = "rockchip,rk3399-pcie-phy";
			status = "okay";
			phandle = <0x19>;
			reset-names = "phy";
		};

		usb2phy@e460 {
			clock-output-names = "clk_usbphy1_480m";
			clock-names = "phyclk";
			clocks = <0x08 0x7c>;
			#clock-cells = <0x00>;
			compatible = "rockchip,rk3399-usb2phy";
			status = "okay";
			reg = <0xe460 0x10>;
			phandle = <0x34>;

			host-port {
				phy-supply = <0xa3>;
				interrupts = <0x00 0x1f 0x04 0x00>;
				#phy-cells = <0x00>;
				status = "okay";
				interrupt-names = "linestate";
				phandle = <0x35>;
			};

			otg-port {
				interrupts = <0x00 0x6c 0x04 0x00 0x00 0x6d 0x04 0x00 0x00 0x6f 0x04 0x00>;
				#phy-cells = <0x00>;
				status = "okay";
				interrupt-names = "otg-bvalid\0otg-id\0linestate";
				phandle = <0x38>;
			};
		};

		usb2phy@e450 {
			clock-output-names = "clk_usbphy0_480m";
			clock-names = "phyclk";
			clocks = <0x08 0x7b>;
			#clock-cells = <0x00>;
			compatible = "rockchip,rk3399-usb2phy";
			status = "okay";
			reg = <0xe450 0x10>;
			phandle = <0x32>;

			port {

				endpoint {
					remote-endpoint = <0xa4>;
					phandle = <0x96>;
				};
			};

			host-port {
				phy-supply = <0xa3>;
				interrupts = <0x00 0x1b 0x04 0x00>;
				#phy-cells = <0x00>;
				status = "okay";
				interrupt-names = "linestate";
				phandle = <0x33>;
			};

			otg-port {
				phy-supply = <0x95>;
				interrupts = <0x00 0x67 0x04 0x00 0x00 0x68 0x04 0x00 0x00 0x6a 0x04 0x00>;
				#phy-cells = <0x00>;
				status = "okay";
				interrupt-names = "otg-bvalid\0otg-id\0linestate";
				phandle = <0x36>;
			};
		};

		io-domains {
			sdmmc-supply = <0x30>;
			audio-supply = <0xa2>;
			gpio1830-supply = <0x83>;
			compatible = "rockchip,rk3399-io-voltage-domain";
			status = "okay";
			phandle = <0x123>;
			bt656-supply = <0x83>;
		};

		phy@f780 {
			clock-names = "emmcclk";
			clocks = <0xa5>;
			drive-impedance-ohm = <0x32>;
			#phy-cells = <0x00>;
			compatible = "rockchip,rk3399-emmc-phy";
			status = "okay";
			reg = <0xf780 0x24>;
			phandle = <0x31>;
		};
	};

	efuse@ff690000 {
		#address-cells = <0x01>;
		clock-names = "pclk_efuse";
		clocks = <0x08 0x17d>;
		#size-cells = <0x01>;
		compatible = "rockchip,rk3399-efuse";
		reg = <0x00 0xff690000 0x00 0x80>;
		phandle = <0x11b>;

		cpu-leakage@1a {
			reg = <0x1a 0x01>;
			phandle = <0x120>;
		};

		center-leakage@19 {
			reg = <0x19 0x01>;
			phandle = <0x11f>;
		};

		logic-leakage@1b {
			reg = <0x1b 0x01>;
			phandle = <0x121>;
		};

		cpu-id@7 {
			reg = <0x07 0x10>;
			phandle = <0x11c>;
		};

		gpu-leakage@18 {
			reg = <0x18 0x01>;
			phandle = <0x11e>;
		};

		wafer-info@1c {
			reg = <0x1c 0x01>;
			phandle = <0x122>;
		};

		cpu-leakage@17 {
			reg = <0x17 0x01>;
			phandle = <0x11d>;
		};
	};

	qos@ffa70080 {
		compatible = "rockchip,rk3399-qos\0syscon";
		reg = <0x00 0xffa70080 0x00 0x20>;
		phandle = <0x7a>;
	};

	interrupt-controller@fee00000 {
		#address-cells = <0x02>;
		interrupts = <0x01 0x09 0x04 0x00>;
		#size-cells = <0x02>;
		compatible = "arm,gic-v3";
		ranges;
		#interrupt-cells = <0x04>;
		reg = <0x00 0xfee00000 0x00 0x10000 0x00 0xfef00000 0x00 0xc0000 0x00 0xfff00000 0x00 0x10000 0x00 0xfff10000 0x00 0x10000 0x00 0xfff20000 0x00 0x10000>;
		phandle = <0x01>;
		interrupt-controller;

		ppi-partitions {

			interrupt-partition-0 {
				affinity = <0x02 0x03 0x04 0x05>;
				phandle = <0x15>;
			};

			interrupt-partition-1 {
				affinity = <0x06 0x07>;
				phandle = <0x16>;
			};
		};

		msi-controller@fee20000 {
			msi-controller;
			compatible = "arm,gic-v3-its";
			reg = <0x00 0xfee20000 0x00 0x20000>;
			phandle = <0x18>;
			#msi-cells = <0x01>;
		};
	};

	i2c@ff160000 {
		pinctrl-names = "default";
		#address-cells = <0x01>;
		pinctrl-0 = <0x44>;
		clock-names = "i2c\0pclk";
		assigned-clocks = <0x08 0x46>;
		assigned-clock-rates = <0xbebc200>;
		interrupts = <0x00 0x24 0x04 0x00>;
		clocks = <0x08 0x46 0x08 0x15a>;
		#size-cells = <0x00>;
		compatible = "rockchip,rk3399-i2c";
		status = "disabled";
		reg = <0x00 0xff160000 0x00 0x1000>;
		phandle = <0xf1>;
	};

	qos@ffa98000 {
		compatible = "rockchip,rk3399-qos\0syscon";
		reg = <0x00 0xffa98000 0x00 0x20>;
		phandle = <0x6e>;
	};

	display-subsystem {
		ports = <0x11 0x12>;
		compatible = "rockchip,display-subsystem";
	};

	dp@fec00000 {
		power-domains = <0x1c 0x15>;
		clock-names = "core-clk\0pclk\0spdif\0grf";
		assigned-clocks = <0x08 0x72 0x08 0xa1>;
		assigned-clock-rates = <0x5f5e100 0xbebc200>;
		resets = <0x08 0x103 0x08 0x148 0x08 0x14a 0x08 0xfd>;
		interrupts = <0x00 0x09 0x04 0x00>;
		clocks = <0x08 0x72 0x08 0x175 0x08 0xa1 0x08 0x16f>;
		#sound-dai-cells = <0x01>;
		compatible = "rockchip,rk3399-cdn-dp";
		status = "disabled";
		rockchip,grf = <0x1d>;
		phys = <0x3a 0x3b>;
		reg = <0x00 0xfec00000 0x00 0x100000>;
		phandle = <0xe9>;
		reset-names = "spdif\0dptx\0apb\0core";

		ports {

			port {
				#address-cells = <0x01>;
				#size-cells = <0x00>;
				phandle = <0xea>;

				endpoint@1 {
					remote-endpoint = <0x3d>;
					reg = <0x01>;
					phandle = <0xb1>;
				};

				endpoint@0 {
					remote-endpoint = <0x3c>;
					reg = <0x00>;
					phandle = <0xb7>;
				};
			};
		};
	};

	adc-keys {
		io-channels = <0xd0 0x01>;
		poll-interval = <0x64>;
		keyup-threshold-microvolt = <0x1b7740>;
		compatible = "adc-keys";
		io-channel-names = "buttons";

		button-up {
			press-threshold-microvolt = <0x186a0>;
			label = "Volume Up";
			linux,code = <0x73>;
		};

		button-menu {
			press-threshold-microvolt = <0x140cd0>;
			label = "Menu";
			linux,code = <0x8b>;
		};

		button-back {
			press-threshold-microvolt = <0xf07a8>;
			label = "Back";
			linux,code = <0x9e>;
		};

		button-down {
			press-threshold-microvolt = <0x493e0>;
			label = "Volume Down";
			linux,code = <0x72>;
		};
	};

	iommu@ff670800 {
		power-domains = <0x1c 0x22>;
		clock-names = "aclk\0iface";
		interrupts = <0x00 0x2a 0x04 0x00>;
		clocks = <0x08 0xe1 0x08 0x1dd>;
		#iommu-cells = <0x00>;
		compatible = "rockchip,iommu";
		status = "disabled";
		reg = <0x00 0xff670800 0x00 0x40>;
		phandle = <0xa0>;
	};

	spi@ff1e0000 {
		pinctrl-names = "default";
		#address-cells = <0x01>;
		pinctrl-0 = <0x5a 0x5b 0x5c 0x5d>;
		clock-names = "spiclk\0apb_pclk";
		interrupts = <0x00 0x34 0x04 0x00>;
		clocks = <0x08 0x49 0x08 0x15d>;
		#size-cells = <0x00>;
		dma-names = "tx\0rx";
		compatible = "rockchip,rk3399-spi\0rockchip,rk3066-spi";
		status = "disabled";
		reg = <0x00 0xff1e0000 0x00 0x1000>;
		phandle = <0xf8>;
		dmas = <0x51 0x0e 0x51 0x0f>;
	};

	vcc5v0-host-regulator {
		pinctrl-names = "default";
		gpio = <0x92 0x19 0x00>;
		pinctrl-0 = <0xd6>;
		regulator-always-on;
		enable-active-high;
		regulator-name = "vcc5v0_host";
		compatible = "regulator-fixed";
		phandle = <0xa3>;
		vin-supply = <0xd5>;
	};

	rga@ff680000 {
		power-domains = <0x1c 0x21>;
		clock-names = "aclk\0hclk\0sclk";
		resets = <0x08 0x6a 0x08 0x67 0x08 0x69>;
		interrupts = <0x00 0x37 0x04 0x00>;
		clocks = <0x08 0xdc 0x08 0x1e5 0x08 0x6d>;
		compatible = "rockchip,rk3399-rga";
		reg = <0x00 0xff680000 0x00 0x10000>;
		phandle = <0x11a>;
		reset-names = "core\0axi\0ahb";
	};

	i2s@ff890000 {
		power-domains = <0x1c 0x1c>;
		pinctrl-names = "default";
		pinctrl-0 = <0xab>;
		clock-names = "i2s_clk\0i2s_hclk";
		interrupts = <0x00 0x28 0x04 0x00>;
		clocks = <0x08 0x57 0x08 0x1d5>;
		dma-names = "tx\0rx";
		#sound-dai-cells = <0x00>;
		compatible = "rockchip,rk3399-i2s\0rockchip,rk3066-i2s";
		status = "disabled";
		reg = <0x00 0xff890000 0x00 0x1000>;
		phandle = <0x129>;
		dmas = <0x62 0x02 0x62 0x03>;
	};

	thermal-zones {
		phandle = <0xfb>;

		cpu-thermal {
			polling-delay = <0x3e8>;
			polling-delay-passive = <0x64>;
			thermal-sensors = <0x67 0x00>;
			phandle = <0xfc>;

			trips {

				cpu_crit {
					temperature = <0x186a0>;
					hysteresis = <0x7d0>;
					type = "critical";
					phandle = <0xfd>;
				};

				cpu_alert0 {
					temperature = <0x14c08>;
					hysteresis = <0x7d0>;
					type = "passive";
					phandle = <0x68>;
				};

				cpu_alert1 {
					temperature = <0x17318>;
					hysteresis = <0x7d0>;
					type = "passive";
					phandle = <0x69>;
				};
			};

			cooling-maps {

				map0 {
					trip = <0x68>;
					cooling-device = <0x06 0xffffffff 0xffffffff 0x07 0xffffffff 0xffffffff>;
				};

				map1 {
					trip = <0x69>;
					cooling-device = <0x02 0xffffffff 0xffffffff 0x03 0xffffffff 0xffffffff 0x04 0xffffffff 0xffffffff 0x05 0xffffffff 0xffffffff 0x06 0xffffffff 0xffffffff 0x07 0xffffffff 0xffffffff>;
				};
			};
		};

		gpu-thermal {
			polling-delay = <0x3e8>;
			polling-delay-passive = <0x64>;
			thermal-sensors = <0x67 0x01>;
			phandle = <0xfe>;

			trips {

				gpu_alert0 {
					temperature = <0x124f8>;
					hysteresis = <0x7d0>;
					type = "passive";
					phandle = <0x6a>;
				};

				gpu_crit {
					temperature = <0x17318>;
					hysteresis = <0x7d0>;
					type = "critical";
					phandle = <0xff>;
				};
			};

			cooling-maps {

				map0 {
					trip = <0x6a>;
					cooling-device = <0x6b 0xffffffff 0xffffffff>;
				};
			};
		};
	};

	isp1@ff920000 {
		power-domains = <0x1c 0x14>;
		iommus = <0xba>;
		phy-names = "dphy";
		clock-names = "isp\0aclk\0hclk";
		interrupts = <0x00 0x2c 0x04 0x00>;
		clocks = <0x08 0x6f 0x08 0xea 0x08 0x1e4>;
		compatible = "rockchip,rk3399-cif-isp";
		status = "disabled";
		phys = <0xbb>;
		reg = <0x00 0xff920000 0x00 0x4000>;
		phandle = <0x12d>;

		ports {
			#address-cells = <0x01>;
			#size-cells = <0x00>;

			port@0 {
				#address-cells = <0x01>;
				#size-cells = <0x00>;
				reg = <0x00>;
			};
		};
	};

	video-codec@ff650000 {
		power-domains = <0x1c 0x1f>;
		iommus = <0x9e>;
		clock-names = "aclk\0hclk";
		interrupts = <0x00 0x72 0x04 0x00 0x00 0x71 0x04 0x00>;
		clocks = <0x08 0xeb 0x08 0x1ea>;
		compatible = "rockchip,rk3399-vpu";
		interrupt-names = "vepu\0vdpu";
		reg = <0x00 0xff650000 0x00 0x800>;
		phandle = <0x117>;
	};

	pmu_a72 {
		interrupts = <0x01 0x07 0x08 0x16>;
		compatible = "arm,cortex-a72-pmu";
	};

	iommu@ff914000 {
		power-domains = <0x1c 0x13>;
		clock-names = "aclk\0iface";
		interrupts = <0x00 0x2b 0x04 0x00>;
		clocks = <0x08 0xe9 0x08 0x1e3>;
		#iommu-cells = <0x00>;
		compatible = "rockchip,iommu";
		rockchip,disable-mmu-reset;
		reg = <0x00 0xff914000 0x00 0x100 0x00 0xff915000 0x00 0x100>;
		phandle = <0xb8>;
	};

	qos@ffaa0000 {
		compatible = "rockchip,rk3399-qos\0syscon";
		reg = <0x00 0xffaa0000 0x00 0x20>;
		phandle = <0x7c>;
	};

	crypto@ff8b0000 {
		clock-names = "hclk_master\0hclk_slave\0sclk";
		resets = <0x08 0xb5 0x08 0xae 0x08 0xaf>;
		interrupts = <0x00 0x00 0x04 0x00>;
		clocks = <0x08 0x1d0 0x08 0x1d2 0x08 0x85>;
		compatible = "rockchip,rk3399-crypto";
		reg = <0x00 0xff8b0000 0x00 0x4000>;
		phandle = <0xeb>;
		reset-names = "master\0slave\0crypto-rst";
	};

	psci {
		method = "smc";
		compatible = "arm,psci-1.0";
	};

	xin24m {
		clock-output-names = "xin24m";
		#clock-cells = <0x00>;
		clock-frequency = <0x16e3600>;
		compatible = "fixed-clock";
		phandle = <0xa1>;
	};

	spi@ff200000 {
		power-domains = <0x1c 0x1c>;
		pinctrl-names = "default";
		#address-cells = <0x01>;
		pinctrl-0 = <0x63 0x64 0x65 0x66>;
		clock-names = "spiclk\0apb_pclk";
		interrupts = <0x00 0x84 0x04 0x00>;
		clocks = <0x08 0x4b 0x08 0x15f>;
		#size-cells = <0x00>;
		dma-names = "tx\0rx";
		compatible = "rockchip,rk3399-spi\0rockchip,rk3066-spi";
		status = "disabled";
		reg = <0x00 0xff200000 0x00 0x1000>;
		phandle = <0xfa>;
		dmas = <0x62 0x08 0x62 0x09>;
	};

	dp@ff970000 {
		power-domains = <0x1c 0x19>;
		pinctrl-names = "default";
		pinctrl-0 = <0xc5>;
		clock-names = "dp\0pclk\0grf";
		resets = <0x08 0x11d>;
		interrupts = <0x00 0x0a 0x04 0x00>;
		clocks = <0x08 0x16a 0x08 0x16c 0x08 0x16f>;
		compatible = "rockchip,rk3399-edp";
		status = "disabled";
		rockchip,grf = <0x1d>;
		reg = <0x00 0xff970000 0x00 0x8000>;
		phandle = <0x136>;
		reset-names = "dp";

		ports {
			#address-cells = <0x01>;
			#size-cells = <0x00>;

			port@0 {
				#address-cells = <0x01>;
				#size-cells = <0x00>;
				reg = <0x00>;
				phandle = <0x137>;

				endpoint@1 {
					remote-endpoint = <0xc7>;
					reg = <0x01>;
					phandle = <0xae>;
				};

				endpoint@0 {
					remote-endpoint = <0xc6>;
					reg = <0x00>;
					phandle = <0xb3>;
				};
			};

			port@1 {
				reg = <0x01>;
				phandle = <0x138>;
			};
		};
	};

	qos@ffae0000 {
		compatible = "rockchip,rk3399-qos\0syscon";
		reg = <0x00 0xffae0000 0x00 0x20>;
		phandle = <0x74>;
	};

	vdd-log {
		regulator-max-microvolt = <0x155cc0>;
		regulator-boot-on;
		regulator-always-on;
		regulator-min-microvolt = "\0\f5";
		regulator-name = "vdd_log";
		compatible = "pwm-regulator";
		phandle = <0x170>;
		pwms = <0xd9 0x00 0x61a8 0x01>;
		pwm-supply = <0xd5>;
	};

	qos@ffab0080 {
		compatible = "rockchip,rk3399-qos\0syscon";
		reg = <0x00 0xffab0080 0x00 0x20>;
		phandle = <0x70>;
	};

	vcc1v8-s3 {
		regulator-max-microvolt = <0x1b7740>;
		regulator-boot-on;
		regulator-always-on;
		regulator-min-microvolt = <0x1b7740>;
		regulator-name = "vcc1v8_s3";
		compatible = "regulator-fixed";
		phandle = <0x3e>;
		vin-supply = <0x4d>;
	};

	iommu@ff903f00 {
		power-domains = <0x1c 0x11>;
		clock-names = "aclk\0iface";
		interrupts = <0x00 0x76 0x04 0x00>;
		clocks = <0x08 0xd9 0x08 0x1d9>;
		#iommu-cells = <0x00>;
		compatible = "rockchip,iommu";
		status = "okay";
		reg = <0x00 0xff903f00 0x00 0x100>;
		phandle = <0xb2>;
	};

	dsi@ff960000 {
		power-domains = <0x1c 0x0f>;
		#address-cells = <0x01>;
		clock-names = "ref\0pclk\0phy_cfg\0grf";
		resets = <0x08 0xfb>;
		interrupts = <0x00 0x2d 0x04 0x00>;
		clocks = <0x08 0xa2 0x08 0x170 0x08 0xa3 0x08 0x16f>;
		#size-cells = <0x00>;
		compatible = "rockchip,rk3399-mipi-dsi\0snps,dw-mipi-dsi";
		status = "disabled";
		rockchip,grf = <0x1d>;
		reg = <0x00 0xff960000 0x00 0x8000>;
		phandle = <0x131>;
		reset-names = "apb";

		ports {
			#address-cells = <0x01>;
			#size-cells = <0x00>;

			port@0 {
				#address-cells = <0x01>;
				#size-cells = <0x00>;
				reg = <0x00>;
				phandle = <0x132>;

				endpoint@1 {
					remote-endpoint = <0xc2>;
					reg = <0x01>;
					phandle = <0xad>;
				};

				endpoint@0 {
					remote-endpoint = <0xc1>;
					reg = <0x00>;
					phandle = <0xb4>;
				};
			};

			port@1 {
				reg = <0x01>;
				phandle = <0x133>;
			};
		};
	};

	qos@ffa76000 {
		compatible = "rockchip,rk3399-qos\0syscon";
		reg = <0x00 0xffa76000 0x00 0x20>;
		phandle = <0x78>;
	};

	serial@ff1b0000 {
		reg-io-width = <0x04>;
		pinctrl-names = "default";
		pinctrl-0 = <0x50>;
		clock-names = "baudclk\0apb_pclk";
		interrupts = <0x00 0x65 0x04 0x00>;
		clocks = <0x08 0x54 0x08 0x163>;
		compatible = "rockchip,rk3399-uart\0snps,dw-apb-uart";
		status = "disabled";
		reg = <0x00 0xff1b0000 0x00 0x100>;
		phandle = <0xf5>;
		reg-shift = <0x02>;
	};

	watchdog@ff848000 {
		interrupts = <0x00 0x78 0x04 0x00>;
		clocks = <0x08 0x17c>;
		compatible = "rockchip,rk3399-wdt\0snps,dw-wdt";
		reg = <0x00 0xff848000 0x00 0x100>;
	};

	qos@ffaa8080 {
		compatible = "rockchip,rk3399-qos\0syscon";
		reg = <0x00 0xffaa8080 0x00 0x20>;
		phandle = <0x7f>;
	};

	qos@ffa70000 {
		compatible = "rockchip,rk3399-qos\0syscon";
		reg = <0x00 0xffa70000 0x00 0x20>;
		phandle = <0x79>;
	};

	i2c@ff130000 {
		pinctrl-names = "default";
		#address-cells = <0x01>;
		pinctrl-0 = <0x41>;
		clock-names = "i2c\0pclk";
		assigned-clocks = <0x08 0x43>;
		i2c-scl-rising-time-ns = <0x1c2>;
		i2c-scl-falling-time-ns = <0x0f>;
		assigned-clock-rates = <0xbebc200>;
		interrupts = <0x00 0x22 0x04 0x00>;
		clocks = <0x08 0x43 0x08 0x157>;
		#size-cells = <0x00>;
		compatible = "rockchip,rk3399-i2c";
		status = "okay";
		reg = <0x00 0xff130000 0x00 0x1000>;
		phandle = <0xbe>;
	};

	mmc@fe330000 {
		power-domains = <0x1c 0x17>;
		mmc-hs400-enhanced-strobe;
		disable-cqe-dcmd;
		clock-output-names = "emmc_cardclock";
		phy-names = "phy_arasan";
		clock-names = "clk_xin\0clk_ahb";
		assigned-clocks = <0x08 0x4e>;
		bus-width = <0x08>;
		non-removable;
		assigned-clock-rates = <0xbebc200>;
		mmc-hs400-1_8v;
		interrupts = <0x00 0x0b 0x04 0x00>;
		clocks = <0x08 0x4e 0x08 0xf0>;
		arasan,soc-ctl-syscon = <0x1d>;
		#clock-cells = <0x00>;
		compatible = "rockchip,rk3399-sdhci-5.1\0arasan,sdhci-5.1";
		status = "okay";
		phys = <0x31>;
		reg = <0x00 0xfe330000 0x00 0x10000>;
		phandle = <0xa5>;
	};

	gpio-keys {
		autorepeat;
		compatible = "gpio-keys";
		phandle = <0x16e>;

		key-power {
			pinctrl-names = "default";
			pinctrl-0 = <0xd1>;
			wakeup-source;
			label = "GPIO Power";
			linux,input-type = <0x01>;
			linux,code = <0x74>;
			debounce-interval = <0x64>;
			gpios = <0x29 0x05 0x01>;
		};
	};

	opp-table-2 {
		compatible = "operating-points-v2";
		phandle = <0xc8>;

		opp04 {
			opp-microvolt = <0xe1d48 0xe1d48 0x118c30>;
			opp-hz = <0x00 0x23c34600>;
		};

		opp02 {
			opp-microvolt = <0xc96a8 0xc96a8 0x118c30>;
			opp-hz = <0x00 0x17d78400>;
		};

		opp00 {
			opp-microvolt = <0xc96a8 0xc96a8 0x118c30>;
			opp-hz = <0x00 0xbebc200>;
		};

		opp05 {
			opp-microvolt = <0x10c8e0 0x10c8e0 0x118c30>;
			opp-hz = <0x00 0x2faf0800>;
		};

		opp03 {
			opp-microvolt = <0xd59f8 0xd59f8 0x118c30>;
			opp-hz = <0x00 0x1dcd6500>;
		};

		opp01 {
			opp-microvolt = <0xc96a8 0xc96a8 0x118c30>;
			opp-hz = <0x00 0x11b3dc40>;
		};
	};

	tsadc@ff260000 {
		pinctrl-names = "init\0default\0sleep";
		pinctrl-2 = <0x6c>;
		pinctrl-0 = <0x6c>;
		clock-names = "tsadc\0apb_pclk";
		rockchip,hw-tshut-polarity = <0x01>;
		assigned-clocks = <0x08 0x4f>;
		assigned-clock-rates = <0xb71b0>;
		resets = <0x08 0xe8>;
		interrupts = <0x00 0x61 0x04 0x00>;
		rockchip,hw-tshut-mode = <0x01>;
		clocks = <0x08 0x4f 0x08 0x164>;
		#thermal-sensor-cells = <0x01>;
		compatible = "rockchip,rk3399-tsadc";
		pinctrl-1 = <0x6d>;
		status = "okay";
		rockchip,grf = <0x1d>;
		reg = <0x00 0xff260000 0x00 0x100>;
		phandle = <0x67>;
		reset-names = "tsadc-apb";
		rockchip,hw-tshut-temp = <0x17318>;
	};

	usb@fe900000 {
		#address-cells = <0x02>;
		clock-names = "ref_clk\0suspend_clk\0bus_clk\0aclk_usb3_rksoc_axi_perf\0aclk_usb3\0grf_clk";
		resets = <0x08 0x126>;
		clocks = <0x08 0x82 0x08 0x84 0x08 0xf7 0x08 0xf8 0x08 0xf4 0x08 0xf9>;
		#size-cells = <0x02>;
		compatible = "rockchip,rk3399-dwc3";
		ranges;
		status = "okay";
		phandle = <0xe7>;
		reset-names = "usb3-otg";

		usb@fe900000 {
			power-domains = <0x1c 0x18>;
			snps,dis_enblslpm_quirk;
			phy-names = "usb2-phy\0usb3-phy";
			clock-names = "ref\0bus_early\0suspend";
			snps,dis-u2-freeclk-exists-quirk;
			phy_type = "utmi_wide";
			snps,dis_u2_susphy_quirk;
			interrupts = <0x00 0x6e 0x04 0x00>;
			clocks = <0x08 0x82 0x08 0xf7 0x08 0x84>;
			compatible = "snps,dwc3";
			snps,dis-del-phy-power-chg-quirk;
			status = "okay";
			snps,xhci-trb-ent-quirk;
			phys = <0x38 0x39>;
			reg = <0x00 0xfe900000 0x00 0x100000>;
			phandle = <0xe8>;
			dr_mode = "host";
			snps,dis-tx-ipgap-linecheck-quirk;
		};
	};

	serial@ff180000 {
		reg-io-width = <0x04>;
		pinctrl-names = "default";
		pinctrl-0 = <0x45 0x46 0x47>;
		clock-names = "baudclk\0apb_pclk";
		interrupts = <0x00 0x63 0x04 0x00>;
		clocks = <0x08 0x51 0x08 0x160>;
		compatible = "rockchip,rk3399-uart\0snps,dw-apb-uart";
		status = "okay";
		reg = <0x00 0xff180000 0x00 0x100>;
		phandle = <0xf2>;
		reg-shift = <0x02>;

		bluetooth {
			device-wakeup-gpios = <0x1a 0x1a 0x00>;
			pinctrl-names = "default";
			pinctrl-0 = <0x49 0x4a 0x4b>;
			clock-names = "lpo";
			clocks = <0x48 0x01>;
			shutdown-gpios = <0x29 0x09 0x00>;
			compatible = "brcm,bcm43438-bt";
			vddio-supply = <0x4d>;
			vbat-supply = <0x4c>;
			host-wakeup-gpios = <0x29 0x04 0x00>;
		};
	};

	usb@fe380000 {
		phy-names = "usb";
		interrupts = <0x00 0x1a 0x04 0x00>;
		clocks = <0x08 0x1c8 0x08 0x1c9 0x32>;
		compatible = "generic-ehci";
		status = "okay";
		phys = <0x33>;
		reg = <0x00 0xfe380000 0x00 0x20000>;
		phandle = <0xe1>;
	};

	ethernet@fe300000 {
		power-domains = <0x1c 0x16>;
		pinctrl-names = "default";
		phy-supply = <0x1f>;
		phy-mode = "rgmii";
		snps,txpbl = <0x04>;
		pinctrl-0 = <0x21 0x22 0x23>;
		clock-names = "stmmaceth\0mac_clk_rx\0mac_clk_tx\0clk_mac_ref\0clk_mac_refout\0aclk_mac\0pclk_mac";
		assigned-clocks = <0x08 0xa6>;
		assigned-clock-parents = <0x1e>;
		local-mac-address = [3e b2 ac ce 3b c6];
		resets = <0x08 0x89>;
		interrupts = <0x00 0x0c 0x04 0x00>;
		clocks = <0x08 0x69 0x08 0x67 0x08 0x68 0x08 0x66 0x08 0x6a 0x08 0xd5 0x08 0x166>;
		clock_in_out = "input";
		compatible = "rockchip,rk3399-gmac";
		status = "okay";
		rockchip,grf = <0x1d>;
		interrupt-names = "macirq";
		reg = <0x00 0xfe300000 0x00 0x10000>;
		rx_delay = <0x11>;
		phandle = <0xdd>;
		phy-handle = <0x20>;
		reset-names = "stmmaceth";
		tx_delay = <0x28>;

		mdio {
			#address-cells = <0x01>;
			#size-cells = <0x00>;
			compatible = "snps,dwmac-mdio";

			ethernet-phy@1 {
				reset-deassert-us = <0x7530>;
				interrupts = <0x0a 0x08>;
				interrupt-parent = <0x24>;
				reset-assert-us = <0x2710>;
				reset-gpios = <0x24 0x0f 0x01>;
				reg = <0x01>;
				phandle = <0x20>;
			};
		};
	};

	debug@fe434000 {
		clock-names = "apb_pclk";
		clocks = <0x08 0x14d>;
		cpu = <0x04>;
		compatible = "arm,coresight-cpu-debug\0arm,primecell";
		reg = <0x00 0xfe434000 0x00 0x1000>;
	};

	spi@ff350000 {
		pinctrl-names = "default";
		#address-cells = <0x01>;
		pinctrl-0 = <0x85 0x86 0x87 0x88>;
		clock-names = "spiclk\0apb_pclk";
		interrupts = <0x00 0x3c 0x04 0x00>;
		clocks = <0x84 0x03 0x84 0x1f>;
		#size-cells = <0x00>;
		compatible = "rockchip,rk3399-spi\0rockchip,rk3066-spi";
		status = "disabled";
		reg = <0x00 0xff350000 0x00 0x1000>;
		phandle = <0x106>;
	};

	vcc3v3-sys {
		regulator-max-microvolt = <0x325aa0>;
		regulator-boot-on;
		regulator-always-on;
		regulator-min-microvolt = <0x325aa0>;
		regulator-name = "vcc3v3_sys";
		compatible = "regulator-fixed";
		phandle = <0x4c>;
		vin-supply = <0xd5>;
	};

	spi@ff1f0000 {
		pinctrl-names = "default";
		#address-cells = <0x01>;
		pinctrl-0 = <0x5e 0x5f 0x60 0x61>;
		clock-names = "spiclk\0apb_pclk";
		interrupts = <0x00 0x43 0x04 0x00>;
		clocks = <0x08 0x4a 0x08 0x15e>;
		#size-cells = <0x00>;
		dma-names = "tx\0rx";
		compatible = "rockchip,rk3399-spi\0rockchip,rk3066-spi";
		status = "disabled";
		reg = <0x00 0xff1f0000 0x00 0x1000>;
		phandle = <0xf9>;
		dmas = <0x51 0x12 0x51 0x13>;
	};

	syscon@ff320000 {
		compatible = "rockchip,rk3399-pmugrf\0syscon\0simple-mfd";
		reg = <0x00 0xff320000 0x00 0x1000>;
		phandle = <0x13>;

		io-domains {
			compatible = "rockchip,rk3399-pmu-io-voltage-domain";
			status = "okay";
			pmu1830-supply = <0x83>;
			phandle = <0x105>;
		};
	};

	iommu@ff8f3f00 {
		power-domains = <0x1c 0x12>;
		clock-names = "aclk\0iface";
		interrupts = <0x00 0x77 0x04 0x00>;
		clocks = <0x08 0xdb 0x08 0x1db>;
		#iommu-cells = <0x00>;
		compatible = "rockchip,iommu";
		status = "okay";
		reg = <0x00 0xff8f3f00 0x00 0x100>;
		phandle = <0xac>;
	};

	timer {
		arm,no-tick-in-suspend;
		interrupts = <0x01 0x0d 0x08 0x00 0x01 0x0e 0x08 0x00 0x01 0x0b 0x08 0x00 0x01 0x0a 0x08 0x00>;
		compatible = "arm,armv8-timer";
	};

	video-codec@ff660000 {
		power-domains = <0x1c 0x20>;
		iommus = <0x9f>;
		clock-names = "axi\0ahb\0cabac\0core";
		interrupts = <0x00 0x74 0x04 0x00>;
		clocks = <0x08 0xed 0x08 0x1ec 0x08 0x9f 0x08 0x9e>;
		compatible = "rockchip,rk3399-vdec";
		reg = <0x00 0xff660000 0x00 0x480>;
		phandle = <0x118>;
	};

	opp-table-0 {
		opp-shared;
		compatible = "operating-points-v2";
		phandle = <0x0c>;

		opp04 {
			opp-microvolt = <0xf4240 0xf4240 0x1312d0>;
			opp-hz = <0x00 0x47868c00>;
		};

		opp02 {
			opp-microvolt = <0xcf850 0xcf850 0x1312d0>;
			opp-hz = <0x00 0x30a32c00>;
		};

		opp00 {
			opp-microvolt = <0xc96a8 0xc96a8 0x1312d0>;
			opp-hz = <0x00 0x18519600>;
			clock-latency-ns = <0x9c40>;
		};

		opp05 {
			opp-microvolt = <0x112a88 0x112a88 0x1312d0>;
			opp-hz = <0x00 0x54667200>;
		};

		opp03 {
			opp-microvolt = <0xe1d48 0xe1d48 0x1312d0>;
			opp-hz = <0x00 0x3c14dc00>;
		};

		opp01 {
			opp-microvolt = <0xc96a8 0xc96a8 0x1312d0>;
			opp-hz = <0x00 0x23c34600>;
		};
	};

	sdio-pwrseq {
		pinctrl-names = "default";
		pinctrl-0 = <0xd2>;
		clock-names = "ext_clock";
		clocks = <0x48 0x01>;
		reset-gpios = <0x29 0x0a 0x01>;
		compatible = "mmc-pwrseq-simple";
		phandle = <0x25>;
	};

	iommu@ff924000 {
		power-domains = <0x1c 0x14>;
		clock-names = "aclk\0iface";
		interrupts = <0x00 0x2c 0x04 0x00>;
		clocks = <0x08 0xea 0x08 0x1e4>;
		#iommu-cells = <0x00>;
		compatible = "rockchip,iommu";
		rockchip,disable-mmu-reset;
		reg = <0x00 0xff924000 0x00 0x100 0x00 0xff925000 0x00 0x100>;
		phandle = <0xba>;
	};

	i2c@ff3c0000 {
		pinctrl-names = "default";
		#address-cells = <0x01>;
		pinctrl-0 = <0x8a>;
		clock-names = "i2c\0pclk";
		assigned-clocks = <0x84 0x09>;
		i2c-scl-rising-time-ns = <0xa8>;
		i2c-scl-falling-time-ns = <0x04>;
		assigned-clock-rates = <0xbebc200>;
		interrupts = <0x00 0x39 0x04 0x00>;
		clocks = <0x84 0x09 0x84 0x1b>;
		#size-cells = <0x00>;
		clock-frequency = <0x61a80>;
		compatible = "rockchip,rk3399-i2c";
		status = "okay";
		reg = <0x00 0xff3c0000 0x00 0x1000>;
		phandle = <0x108>;

		pmic@1b {
			vcc11-supply = <0x4c>;
			pinctrl-names = "default";
			vcc12-supply = <0x4c>;
			rockchip,system-power-controller;
			clock-output-names = "rtc_clko_soc\0rtc_clko_wifi";
			pinctrl-0 = <0x8c>;
			wakeup-source;
			interrupts = <0x15 0x08>;
			#clock-cells = <0x01>;
			interrupt-parent = <0x8b>;
			vcc1-supply = <0x4c>;
			vcc2-supply = <0x4c>;
			compatible = "rockchip,rk808";
			vddio-supply = <0x83>;
			vcc3-supply = <0x4c>;
			vcc4-supply = <0x4c>;
			reg = <0x1b>;
			phandle = <0x48>;
			vcc6-supply = <0x4c>;
			vcc7-supply = <0x4c>;
			vcc8-supply = <0x4c>;
			vcc9-supply = <0x4c>;
			vcc10-supply = <0x4c>;

			regulators {

				DCDC_REG4 {
					regulator-max-microvolt = <0x325aa0>;
					regulator-boot-on;
					regulator-always-on;
					regulator-min-microvolt = <0x1b7740>;
					regulator-name = "vcc_1v8";
					phandle = <0x4d>;

					regulator-state-mem {
						regulator-suspend-microvolt = <0x1b7740>;
						regulator-on-in-suspend;
					};
				};

				LDO_REG4 {
					regulator-max-microvolt = <0x33e140>;
					regulator-boot-on;
					regulator-always-on;
					regulator-min-microvolt = <0x1b7740>;
					regulator-name = "vcc_sdio";
					phandle = <0x30>;

					regulator-state-mem {
						regulator-suspend-microvolt = <0x2dc6c0>;
						regulator-on-in-suspend;
					};
				};

				DCDC_REG2 {
					regulator-max-microvolt = <0x16e360>;
					regulator-boot-on;
					regulator-always-on;
					regulator-min-microvolt = <0xaae60>;
					regulator-name = "vdd_cpu_l";
					regulator-ramp-delay = <0x1771>;
					phandle = <0x0d>;

					regulator-state-mem {
						regulator-off-in-suspend;
					};
				};

				LDO_REG2 {
					regulator-max-microvolt = <0x33e140>;
					regulator-boot-on;
					regulator-always-on;
					regulator-min-microvolt = <0x1b7740>;
					regulator-name = "vcc3v0_tp";
					phandle = <0x10c>;

					regulator-state-mem {
						regulator-off-in-suspend;
					};
				};

				SWITCH_REG1 {
					regulator-boot-on;
					regulator-always-on;
					regulator-name = "vcc3v3_s3";
					phandle = <0x1f>;

					regulator-state-mem {
						regulator-off-in-suspend;
					};
				};

				LDO_REG7 {
					regulator-max-microvolt = <0x2625a0>;
					regulator-boot-on;
					regulator-always-on;
					regulator-min-microvolt = "\0\f5";
					regulator-name = "vcca1v8_codec";
					phandle = <0xa2>;

					regulator-state-mem {
						regulator-off-in-suspend;
					};
				};

				LDO_REG5 {
					regulator-max-microvolt = <0x33e140>;
					regulator-boot-on;
					regulator-always-on;
					regulator-min-microvolt = <0x1b7740>;
					regulator-name = "vcca3v0_codec";
					phandle = <0x10e>;

					regulator-state-mem {
						regulator-off-in-suspend;
					};
				};

				DCDC_REG3 {
					regulator-boot-on;
					regulator-always-on;
					regulator-name = "vcc_ddr";
					phandle = <0x10a>;

					regulator-state-mem {
						regulator-on-in-suspend;
					};
				};

				LDO_REG3 {
					regulator-max-microvolt = <0x2625a0>;
					regulator-boot-on;
					regulator-always-on;
					regulator-min-microvolt = "\0\f5";
					regulator-name = "vcc1v8_pmupll";
					phandle = <0x10d>;

					regulator-state-mem {
						regulator-suspend-microvolt = <0x1b7740>;
						regulator-on-in-suspend;
					};
				};

				DCDC_REG1 {
					regulator-max-microvolt = <0x16e360>;
					regulator-boot-on;
					regulator-always-on;
					regulator-min-microvolt = <0xaae60>;
					regulator-name = "vdd_center";
					regulator-ramp-delay = <0x1771>;
					phandle = <0x109>;

					regulator-state-mem {
						regulator-off-in-suspend;
					};
				};

				LDO_REG1 {
					regulator-max-microvolt = <0x33e140>;
					regulator-boot-on;
					regulator-always-on;
					regulator-min-microvolt = <0x1b7740>;
					regulator-name = "vcc1v8_dvp";
					phandle = <0x10b>;

					regulator-state-mem {
						regulator-off-in-suspend;
					};
				};

				SWITCH_REG2 {
					regulator-boot-on;
					regulator-always-on;
					regulator-name = "vcc3v3_s0";
					phandle = <0x110>;

					regulator-state-mem {
						regulator-off-in-suspend;
					};
				};

				LDO_REG8 {
					regulator-max-microvolt = <0x33e140>;
					regulator-boot-on;
					regulator-always-on;
					regulator-min-microvolt = <0x1b7740>;
					regulator-name = "vcc_3v0";
					phandle = <0x83>;

					regulator-state-mem {
						regulator-suspend-microvolt = <0x2dc6c0>;
						regulator-on-in-suspend;
					};
				};

				LDO_REG6 {
					regulator-max-microvolt = <0x2625a0>;
					regulator-boot-on;
					regulator-always-on;
					regulator-min-microvolt = "\0\f5";
					regulator-name = "vcc_1v5";
					phandle = <0x10f>;

					regulator-state-mem {
						regulator-suspend-microvolt = <0x16e360>;
						regulator-on-in-suspend;
					};
				};
			};
		};

		regulator@41 {
			regulator-max-microvolt = <0x16e360>;
			pinctrl-names = "default";
			regulator-boot-on;
			pinctrl-0 = <0x8e>;
			regulator-always-on;
			regulator-min-microvolt = <0xadf34>;
			regulator-name = "vdd_gpu";
			regulator-ramp-delay = <0x3e8>;
			fcs,suspend-voltage-selector = <0x01>;
			compatible = "silergy,syr828";
			reg = <0x41>;
			phandle = <0xc9>;
			vin-supply = <0x4c>;

			regulator-state-mem {
				regulator-off-in-suspend;
			};
		};

		regulator@40 {
			regulator-max-microvolt = <0x16e360>;
			pinctrl-names = "default";
			regulator-boot-on;
			pinctrl-0 = <0x8d>;
			regulator-always-on;
			regulator-min-microvolt = <0xadf34>;
			regulator-name = "vdd_cpu_b";
			regulator-ramp-delay = <0x3e8>;
			fcs,suspend-voltage-selector = <0x01>;
			compatible = "silergy,syr827";
			reg = <0x40>;
			phandle = <0x10>;
			vin-supply = <0x4c>;

			regulator-state-mem {
				regulator-off-in-suspend;
			};
		};
	};

	qos@ffab0000 {
		compatible = "rockchip,rk3399-qos\0syscon";
		reg = <0x00 0xffab0000 0x00 0x20>;
		phandle = <0x6f>;
	};

	hdmi@ff940000 {
		power-domains = <0x1c 0x15>;
		reg-io-width = <0x04>;
		clock-names = "iahb\0isfr\0cec\0grf\0ref";
		interrupts = <0x00 0x17 0x04 0x00>;
		clocks = <0x08 0x174 0x08 0x71 0x08 0x70 0x08 0x16f 0x08 0x07>;
		ddc-i2c-bus = <0xbe>;
		#sound-dai-cells = <0x00>;
		compatible = "rockchip,rk3399-dw-hdmi";
		status = "okay";
		rockchip,grf = <0x1d>;
		reg = <0x00 0xff940000 0x00 0x20000>;
		phandle = <0xbd>;

		ports {
			#address-cells = <0x01>;
			#size-cells = <0x00>;

			port@0 {
				#address-cells = <0x01>;
				#size-cells = <0x00>;
				reg = <0x00>;
				phandle = <0x12f>;

				endpoint@1 {
					remote-endpoint = <0xc0>;
					reg = <0x01>;
					phandle = <0xaf>;
				};

				endpoint@0 {
					remote-endpoint = <0xbf>;
					reg = <0x00>;
					phandle = <0xb5>;
				};
			};

			port@1 {
				reg = <0x01>;
				phandle = <0x130>;
			};
		};
	};

	phy@ff800000 {
		power-domains = <0x1c 0x09>;
		clock-names = "tcpdcore\0tcpdphy-ref";
		assigned-clocks = <0x08 0x80>;
		assigned-clock-rates = <0x2faf080>;
		resets = <0x08 0x9d 0x08 0x9c 0x08 0x14d>;
		clocks = <0x08 0x80 0x08 0x7f>;
		compatible = "rockchip,rk3399-typec-phy";
		status = "okay";
		rockchip,grf = <0x1d>;
		reg = <0x00 0xff800000 0x00 0x40000>;
		phandle = <0x125>;
		reset-names = "uphy\0uphy-pipe\0uphy-tcphy";

		dp-port {
			#phy-cells = <0x00>;
			phandle = <0x3b>;
		};

		usb3-port {
			#phy-cells = <0x00>;
			phandle = <0x39>;
		};
	};

	qos@ffaa8000 {
		compatible = "rockchip,rk3399-qos\0syscon";
		reg = <0x00 0xffaa8000 0x00 0x20>;
		phandle = <0x7e>;
	};

	vcc3v3-pcie-regulator {
		pinctrl-names = "default";
		regulator-boot-on;
		gpio = <0x29 0x02 0x00>;
		pinctrl-0 = <0xd4>;
		regulator-always-on;
		enable-active-high;
		regulator-name = "vcc3v3_pcie";
		compatible = "regulator-fixed";
		phandle = <0x16f>;
	};

	clock-controller@ff750000 {
		#reset-cells = <0x01>;
		clock-names = "xin24m";
		assigned-clocks = <0x84 0x01>;
		assigned-clock-rates = <0x284af100>;
		clocks = <0xa1>;
		#clock-cells = <0x01>;
		compatible = "rockchip,rk3399-pmucru";
		rockchip,grf = <0x13>;
		reg = <0x00 0xff750000 0x00 0x1000>;
		phandle = <0x84>;
	};

	crypto@ff8b8000 {
		clock-names = "hclk_master\0hclk_slave\0sclk";
		resets = <0x08 0xba 0x08 0xb8 0x08 0xb9>;
		interrupts = <0x00 0x87 0x04 0x00>;
		clocks = <0x08 0x1d1 0x08 0x1d3 0x08 0x86>;
		compatible = "rockchip,rk3399-crypto";
		reg = <0x00 0xff8b8000 0x00 0x4000>;
		phandle = <0xec>;
		reset-names = "master\0slave\0crypto-rst";
	};

	aliases {
		i2c3 = "/i2c@ff130000";
		ethernet0 = "/ethernet@fe300000";
		spi2 = "/spi@ff1e0000";
		gpio0 = "/pinctrl/gpio@ff720000";
		i2c1 = "/i2c@ff110000";
		spi0 = "/spi@ff1c0000";
		mmc1 = "/mmc@fe320000";
		i2c8 = "/i2c@ff3e0000";
		serial3 = "/serial@ff1b0000";
		i2c6 = "/i2c@ff150000";
		serial1 = "/serial@ff190000";
		spi5 = "/spi@ff200000";
		gpio3 = "/pinctrl/gpio@ff788000";
		i2c4 = "/i2c@ff3d0000";
		spi3 = "/spi@ff350000";
		gpio1 = "/pinctrl/gpio@ff730000";
		i2c2 = "/i2c@ff120000";
		spi1 = "/spi@ff1d0000";
		i2c0 = "/i2c@ff3c0000";
		mmc2 = "/mmc@fe330000";
		serial4 = "/serial@ff370000";
		mmc0 = "/mmc@fe310000";
		i2c7 = "/i2c@ff160000";
		serial2 = "/serial@ff1a0000";
		gpio4 = "/pinctrl/gpio@ff790000";
		i2c5 = "/i2c@ff140000";
		serial0 = "/serial@ff180000";
		spi4 = "/spi@ff1f0000";
		gpio2 = "/pinctrl/gpio@ff780000";
	};

	qos@ffac0080 {
		compatible = "rockchip,rk3399-qos\0syscon";
		reg = <0x00 0xffac0080 0x00 0x20>;
		phandle = <0x73>;
	};

	usb@fe800000 {
		#address-cells = <0x02>;
		clock-names = "ref_clk\0suspend_clk\0bus_clk\0aclk_usb3_rksoc_axi_perf\0aclk_usb3\0grf_clk";
		resets = <0x08 0x125>;
		clocks = <0x08 0x81 0x08 0x83 0x08 0xf6 0x08 0xf8 0x08 0xf4 0x08 0xf9>;
		#size-cells = <0x02>;
		compatible = "rockchip,rk3399-dwc3";
		ranges;
		status = "okay";
		phandle = <0xe5>;
		reset-names = "usb3-otg";

		usb@fe800000 {
			power-domains = <0x1c 0x18>;
			snps,dis_enblslpm_quirk;
			phy-names = "usb2-phy\0usb3-phy";
			clock-names = "ref\0bus_early\0suspend";
			snps,dis-u2-freeclk-exists-quirk;
			phy_type = "utmi_wide";
			snps,dis_u2_susphy_quirk;
			interrupts = <0x00 0x69 0x04 0x00>;
			clocks = <0x08 0x81 0x08 0xf6 0x08 0x83>;
			compatible = "snps,dwc3";
			snps,dis-del-phy-power-chg-quirk;
			status = "okay";
			snps,xhci-trb-ent-quirk;
			phys = <0x36 0x37>;
			reg = <0x00 0xfe800000 0x00 0x100000>;
			phandle = <0xe6>;
			dr_mode = "host";
			snps,dis-tx-ipgap-linecheck-quirk;
		};
	};

	memory-controller {
		clock-names = "dmc_clk";
		clocks = <0x08 0xa8>;
		devfreq-events = <0x14>;
		compatible = "rockchip,rk3399-dmc";
		rockchip,pmu = <0x13>;
		status = "disabled";
		phandle = <0xda>;
	};

	qos@ffa60180 {
		compatible = "rockchip,rk3399-qos\0syscon";
		reg = <0x00 0xffa60180 0x00 0x20>;
		phandle = <0x102>;
	};

	usb@fe3c0000 {
		phy-names = "usb";
		interrupts = <0x00 0x1e 0x04 0x00>;
		clocks = <0x08 0x1ca 0x08 0x1cb 0x34>;
		compatible = "generic-ehci";
		status = "okay";
		phys = <0x35>;
		reg = <0x00 0xfe3c0000 0x00 0x20000>;
		phandle = <0xe3>;
	};

	dsi@ff968000 {
		power-domains = <0x1c 0x0f>;
		#address-cells = <0x01>;
		clock-names = "ref\0pclk\0phy_cfg\0grf";
		resets = <0x08 0xfc>;
		interrupts = <0x00 0x2e 0x04 0x00>;
		clocks = <0x08 0xa2 0x08 0x171 0x08 0xa4 0x08 0x16f>;
		#size-cells = <0x00>;
		#phy-cells = <0x00>;
		compatible = "rockchip,rk3399-mipi-dsi\0snps,dw-mipi-dsi";
		status = "disabled";
		rockchip,grf = <0x1d>;
		reg = <0x00 0xff968000 0x00 0x8000>;
		phandle = <0xbb>;
		reset-names = "apb";

		ports {
			#address-cells = <0x01>;
			#size-cells = <0x00>;

			port@0 {
				#address-cells = <0x01>;
				#size-cells = <0x00>;
				reg = <0x00>;
				phandle = <0x134>;

				endpoint@1 {
					remote-endpoint = <0xc4>;
					reg = <0x01>;
					phandle = <0xb0>;
				};

				endpoint@0 {
					remote-endpoint = <0xc3>;
					reg = <0x00>;
					phandle = <0xb6>;
				};
			};

			port@1 {
				reg = <0x01>;
				phandle = <0x135>;
			};
		};
	};

	i2s@ff8a0000 {
		power-domains = <0x1c 0x1c>;
		clock-names = "i2s_clk\0i2s_hclk";
		interrupts = <0x00 0x29 0x04 0x00>;
		clocks = <0x08 0x58 0x08 0x1d6>;
		dma-names = "tx\0rx";
		#sound-dai-cells = <0x00>;
		compatible = "rockchip,rk3399-i2s\0rockchip,rk3066-i2s";
		status = "disabled";
		reg = <0x00 0xff8a0000 0x00 0x1000>;
		phandle = <0xbc>;
		dmas = <0x62 0x04 0x62 0x05>;
	};

	i2c@ff140000 {
		pinctrl-names = "default";
		#address-cells = <0x01>;
		pinctrl-0 = <0x42>;
		clock-names = "i2c\0pclk";
		assigned-clocks = <0x08 0x44>;
		assigned-clock-rates = <0xbebc200>;
		interrupts = <0x00 0x26 0x04 0x00>;
		clocks = <0x08 0x44 0x08 0x158>;
		#size-cells = <0x00>;
		compatible = "rockchip,rk3399-i2c";
		status = "disabled";
		reg = <0x00 0xff140000 0x00 0x1000>;
		phandle = <0xef>;
	};

	chosen {
		u-boot,version = "2022.07-armbian-2022.07-Se092-P621f-H5921-V75d6-Bb703-R448a";
		linux,initrd-end = <0x00 0xf5f1c0ec>;
		bootargs = "root=UUID=65191409-5cb8-45c3-b8ff-752139c3c17b rootwait rootfstype=ext4 splash=verbose console=ttyS2,1500000 console=tty1 consoleblank=0 loglevel=1 ubootpart=741a6c3d-01 usb-storage.quirks=0x2537:0x1066:u,0x2537:0x1068:u   cgroup_enable=cpuset cgroup_memory=1 cgroup_enable=memory";
		linux,initrd-start = <0x00 0xf4ed5000>;
		stdout-path = "serial2:1500000n8";
	};

	vop@ff900000 {
		power-domains = <0x1c 0x11>;
		iommus = <0xb2>;
		clock-names = "aclk_vop\0dclk_vop\0hclk_vop";
		assigned-clocks = <0x08 0xd9 0x08 0x1d9>;
		assigned-clock-rates = <0x17d78400 0x5f5e100>;
		resets = <0x08 0x112 0x08 0x116 0x08 0x118>;
		interrupts = <0x00 0x76 0x04 0x00>;
		clocks = <0x08 0xd9 0x08 0xb4 0x08 0x1d9>;
		compatible = "rockchip,rk3399-vop-big";
		status = "okay";
		reg = <0x00 0xff900000 0x00 0x2000 0x00 0xff902000 0x00 0x1000>;
		phandle = <0x12b>;
		reset-names = "axi\0ahb\0dclk";

		port {
			#address-cells = <0x01>;
			#size-cells = <0x00>;
			phandle = <0x12>;

			endpoint@3 {
				remote-endpoint = <0xb6>;
				reg = <0x03>;
				phandle = <0xc3>;
			};

			endpoint@1 {
				remote-endpoint = <0xb4>;
				reg = <0x01>;
				phandle = <0xc1>;
			};

			endpoint@4 {
				remote-endpoint = <0xb7>;
				reg = <0x04>;
				phandle = <0x3c>;
			};

			endpoint@2 {
				remote-endpoint = <0xb5>;
				reg = <0x02>;
				phandle = <0xbf>;
			};

			endpoint@0 {
				remote-endpoint = <0xb3>;
				reg = <0x00>;
				phandle = <0xc6>;
			};
		};
	};

	serial@ff190000 {
		reg-io-width = <0x04>;
		pinctrl-names = "default";
		pinctrl-0 = <0x4e>;
		clock-names = "baudclk\0apb_pclk";
		interrupts = <0x00 0x62 0x04 0x00>;
		clocks = <0x08 0x52 0x08 0x161>;
		compatible = "rockchip,rk3399-uart\0snps,dw-apb-uart";
		status = "disabled";
		reg = <0x00 0xff190000 0x00 0x100>;
		phandle = <0xf3>;
		reg-shift = <0x02>;
	};

	iommu@ff650800 {
		power-domains = <0x1c 0x1f>;
		clock-names = "aclk\0iface";
		interrupts = <0x00 0x73 0x04 0x00>;
		clocks = <0x08 0xeb 0x08 0x1ea>;
		#iommu-cells = <0x00>;
		compatible = "rockchip,iommu";
		reg = <0x00 0xff650800 0x00 0x40>;
		phandle = <0x9e>;
	};

	qos@ffa5c000 {
		compatible = "rockchip,rk3399-qos\0syscon";
		reg = <0x00 0xffa5c000 0x00 0x20>;
		phandle = <0x76>;
	};

	spi@ff1c0000 {
		pinctrl-names = "default";
		#address-cells = <0x01>;
		pinctrl-0 = <0x52 0x53 0x54 0x55>;
		clock-names = "spiclk\0apb_pclk";
		interrupts = <0x00 0x44 0x04 0x00>;
		clocks = <0x08 0x47 0x08 0x15b>;
		#size-cells = <0x00>;
		dma-names = "tx\0rx";
		compatible = "rockchip,rk3399-spi\0rockchip,rk3066-spi";
		status = "disabled";
		reg = <0x00 0xff1c0000 0x00 0x1000>;
		phandle = <0xf6>;
		dmas = <0x51 0x0a 0x51 0x0b>;
	};

	dma-controller@ff6d0000 {
		clock-names = "apb_pclk";
		interrupts = <0x00 0x05 0x04 0x00 0x00 0x06 0x04 0x00>;
		clocks = <0x08 0xd3>;
		arm,pl330-periph-burst;
		compatible = "arm,pl330\0arm,primecell";
		reg = <0x00 0xff6d0000 0x00 0x4000>;
		phandle = <0x62>;
		#dma-cells = <0x01>;
	};

	pcie-ep@f8000000 {
		pinctrl-names = "default";
		phy-names = "pcie-phy-0\0pcie-phy-1\0pcie-phy-2\0pcie-phy-3";
		pinctrl-0 = <0x1b>;
		clock-names = "aclk\0aclk-perf\0hclk\0pm";
		reg-names = "apb-base\0mem-base";
		resets = <0x08 0x82 0x08 0x83 0x08 0x84 0x08 0x85 0x08 0x86 0x08 0x81 0x08 0x80>;
		clocks = <0x08 0xc5 0x08 0xc4 0x08 0x147 0x08 0xa0>;
		max-functions = [08];
		num-lanes = <0x04>;
		compatible = "rockchip,rk3399-pcie-ep";
		status = "disabled";
		phys = <0x19 0x00 0x19 0x01 0x19 0x02 0x19 0x03>;
		rockchip,max-outbound-regions = <0x20>;
		reg = <0x00 0xfd000000 0x00 0x1000000 0x00 0xfa000000 0x00 0x2000000>;
		phandle = <0xdc>;
		reset-names = "core\0mgmt\0mgmt-sticky\0pipe\0pm\0pclk\0aclk";
	};

	vbus-typec-regulator {
		pinctrl-names = "default";
		gpio = <0x8b 0x03 0x00>;
		pinctrl-0 = <0xd7>;
		enable-active-high;
		regulator-name = "vbus_typec";
		compatible = "regulator-fixed";
		phandle = <0x95>;
		vin-supply = <0xd5>;
	};

	dc-12v {
		regulator-max-microvolt = <0xb71b00>;
		regulator-boot-on;
		regulator-always-on;
		regulator-min-microvolt = <0xb71b00>;
		regulator-name = "dc_12v";
		compatible = "regulator-fixed";
		phandle = <0xd8>;
	};

	external-gmac-clock {
		clock-output-names = "clkin_gmac";
		#clock-cells = <0x00>;
		clock-frequency = <0x7735940>;
		compatible = "fixed-clock";
		phandle = <0x1e>;
	};

	pmu_a53 {
		interrupts = <0x01 0x07 0x08 0x15>;
		compatible = "arm,cortex-a53-pmu";
	};

	isp0@ff910000 {
		power-domains = <0x1c 0x13>;
		iommus = <0xb8>;
		phy-names = "dphy";
		clock-names = "isp\0aclk\0hclk";
		interrupts = <0x00 0x2b 0x04 0x00>;
		clocks = <0x08 0x6e 0x08 0xe9 0x08 0x1e3>;
		compatible = "rockchip,rk3399-cif-isp";
		status = "disabled";
		phys = <0xb9>;
		reg = <0x00 0xff910000 0x00 0x4000>;
		phandle = <0x12c>;

		ports {
			#address-cells = <0x01>;
			#size-cells = <0x00>;

			port@0 {
				#address-cells = <0x01>;
				#size-cells = <0x00>;
				reg = <0x00>;
			};
		};
	};

	debug@fe436000 {
		clock-names = "apb_pclk";
		clocks = <0x08 0x14d>;
		cpu = <0x05>;
		compatible = "arm,coresight-cpu-debug\0arm,primecell";
		reg = <0x00 0xfe436000 0x00 0x1000>;
	};

	cpus {
		#address-cells = <0x02>;
		#size-cells = <0x00>;

		cpu@1 {
			d-cache-line-size = <0x40>;
			capacity-dmips-mhz = <0x1e5>;
			cpu-supply = <0x0d>;
			clocks = <0x08 0x08>;
			i-cache-line-size = <0x40>;
			cpu-idle-states = <0x09 0x0a>;
			device_type = "cpu";
			compatible = "arm,cortex-a53";
			dynamic-power-coefficient = <0x64>;
			d-cache-size = <0x8000>;
			next-level-cache = <0x0b>;
			i-cache-size = <0x8000>;
			reg = <0x00 0x01>;
			enable-method = "psci";
			phandle = <0x03>;
			d-cache-sets = <0x80>;
			operating-points-v2 = <0x0c>;
			i-cache-sets = <0x100>;
			#cooling-cells = <0x02>;
		};

		cpu@101 {
			d-cache-line-size = <0x40>;
			capacity-dmips-mhz = <0x400>;
			cpu-supply = <0x10>;
			clocks = <0x08 0x09>;
			i-cache-line-size = <0x40>;
			cpu-idle-states = <0x09 0x0a>;
			device_type = "cpu";
			compatible = "arm,cortex-a72";
			dynamic-power-coefficient = <0x1b4>;
			d-cache-size = <0x8000>;
			next-level-cache = <0x0e>;
			i-cache-size = <0xc000>;
			reg = <0x00 0x101>;
			enable-method = "psci";
			phandle = <0x07>;
			d-cache-sets = <0x100>;
			operating-points-v2 = <0x0f>;
			i-cache-sets = <0x100>;
			#cooling-cells = <0x02>;

			thermal-idle {
				exit-latency-us = <0x1f4>;
				duration-us = <0x2710>;
				#cooling-cells = <0x02>;
			};
		};

		idle-states {
			entry-method = "psci";

			cluster-sleep {
				entry-latency-us = <0x190>;
				local-timer-stop;
				exit-latency-us = <0x1f4>;
				arm,psci-suspend-param = <0x1010000>;
				compatible = "arm,idle-state";
				phandle = <0x0a>;
				min-residency-us = <0x7d0>;
			};

			cpu-sleep {
				entry-latency-us = <0x78>;
				local-timer-stop;
				exit-latency-us = <0xfa>;
				arm,psci-suspend-param = <0x10000>;
				compatible = "arm,idle-state";
				phandle = <0x09>;
				min-residency-us = <0x384>;
			};
		};

		l2-cache-cluster1 {
			cache-size = <0x100000>;
			cache-level = <0x02>;
			cache-sets = <0x400>;
			cache-unified;
			compatible = "cache";
			cache-line-size = <0x40>;
			phandle = <0x0e>;
		};

		cpu-map {

			cluster0 {

				core3 {
					cpu = <0x05>;
				};

				core1 {
					cpu = <0x03>;
				};

				core2 {
					cpu = <0x04>;
				};

				core0 {
					cpu = <0x02>;
				};
			};

			cluster1 {

				core1 {
					cpu = <0x07>;
				};

				core0 {
					cpu = <0x06>;
				};
			};
		};

		cpu@2 {
			d-cache-line-size = <0x40>;
			capacity-dmips-mhz = <0x1e5>;
			cpu-supply = <0x0d>;
			clocks = <0x08 0x08>;
			i-cache-line-size = <0x40>;
			cpu-idle-states = <0x09 0x0a>;
			device_type = "cpu";
			compatible = "arm,cortex-a53";
			dynamic-power-coefficient = <0x64>;
			d-cache-size = <0x8000>;
			next-level-cache = <0x0b>;
			i-cache-size = <0x8000>;
			reg = <0x00 0x02>;
			enable-method = "psci";
			phandle = <0x04>;
			d-cache-sets = <0x80>;
			operating-points-v2 = <0x0c>;
			i-cache-sets = <0x100>;
			#cooling-cells = <0x02>;
		};

		cpu@0 {
			d-cache-line-size = <0x40>;
			capacity-dmips-mhz = <0x1e5>;
			cpu-supply = <0x0d>;
			clocks = <0x08 0x08>;
			i-cache-line-size = <0x40>;
			cpu-idle-states = <0x09 0x0a>;
			device_type = "cpu";
			compatible = "arm,cortex-a53";
			dynamic-power-coefficient = <0x64>;
			d-cache-size = <0x8000>;
			next-level-cache = <0x0b>;
			i-cache-size = <0x8000>;
			reg = <0x00 0x00>;
			enable-method = "psci";
			phandle = <0x02>;
			d-cache-sets = <0x80>;
			operating-points-v2 = <0x0c>;
			i-cache-sets = <0x100>;
			#cooling-cells = <0x02>;
		};

		cpu@100 {
			d-cache-line-size = <0x40>;
			capacity-dmips-mhz = <0x400>;
			cpu-supply = <0x10>;
			clocks = <0x08 0x09>;
			i-cache-line-size = <0x40>;
			cpu-idle-states = <0x09 0x0a>;
			device_type = "cpu";
			compatible = "arm,cortex-a72";
			dynamic-power-coefficient = <0x1b4>;
			d-cache-size = <0x8000>;
			next-level-cache = <0x0e>;
			i-cache-size = <0xc000>;
			reg = <0x00 0x100>;
			enable-method = "psci";
			phandle = <0x06>;
			d-cache-sets = <0x100>;
			operating-points-v2 = <0x0f>;
			i-cache-sets = <0x100>;
			#cooling-cells = <0x02>;

			thermal-idle {
				exit-latency-us = <0x1f4>;
				duration-us = <0x2710>;
				#cooling-cells = <0x02>;
			};
		};

		cpu@3 {
			d-cache-line-size = <0x40>;
			capacity-dmips-mhz = <0x1e5>;
			cpu-supply = <0x0d>;
			clocks = <0x08 0x08>;
			i-cache-line-size = <0x40>;
			cpu-idle-states = <0x09 0x0a>;
			device_type = "cpu";
			compatible = "arm,cortex-a53";
			dynamic-power-coefficient = <0x64>;
			d-cache-size = <0x8000>;
			next-level-cache = <0x0b>;
			i-cache-size = <0x8000>;
			reg = <0x00 0x03>;
			enable-method = "psci";
			phandle = <0x05>;
			d-cache-sets = <0x80>;
			operating-points-v2 = <0x0c>;
			i-cache-sets = <0x100>;
			#cooling-cells = <0x02>;
		};

		l2-cache-cluster0 {
			cache-size = <0x80000>;
			cache-level = <0x02>;
			cache-sets = <0x200>;
			cache-unified;
			compatible = "cache";
			cache-line-size = <0x40>;
			phandle = <0x0b>;
		};
	};

	__symbols__ {
		i2s0_2ch_bus = "/pinctrl/i2s0/i2s0-2ch-bus";
		i2c3 = "/i2c@ff130000";
		usb_host1_ohci = "/usb@fe3e0000";
		spi5_clk = "/pinctrl/spi5/spi5-clk";
		vcc3v3_s3 = "/i2c@ff3c0000/pmic@1b/regulators/SWITCH_REG1";
		typec_hs = "/i2c@ff3d0000/fusb302@22/connector/ports/port@0/endpoint";
		sdmmc_clk = "/pinctrl/sdmmc/sdmmc-clk";
		dc_12v = "/dc-12v";
		vopl_out_mipi = "/vop@ff8f0000/port/endpoint@0";
		tcphy1 = "/phy@ff800000";
		cpu_crit = "/thermal-zones/cpu-thermal/trips/cpu_crit";
		thermal_zones = "/thermal-zones";
		qos_gpu = "/qos@ffae0000";
		qos_iep = "/qos@ffa98000";
		cpu_b_sleep = "/pinctrl/pmic/cpu-b-sleep";
		clk_32k = "/pinctrl/clock/clk-32k";
		cpu_l1 = "/cpus/cpu@1";
		vcc3v3_pcie = "/vcc3v3-pcie-regulator";
		spi2 = "/spi@ff1e0000";
		pcfg_pull_down_12ma = "/pinctrl/pcfg-pull-down-12ma";
		qos_isp0_m0 = "/qos@ffaa0000";
		gpio0 = "/pinctrl/gpio@ff720000";
		spi4_tx = "/pinctrl/spi4/spi4-tx";
		saradc = "/saradc@ff100000";
		test_clkout1 = "/pinctrl/testclk/test-clkout1";
		vop0_pwm_pin = "/pinctrl/pwm0/vop0-pwm-pin";
		cluster1_opp = "/opp-table-1";
		mipi1_in_vopl = "/dsi@ff968000/ports/port@0/endpoint@1";
		spi0_cs0 = "/pinctrl/spi0/spi0-cs0";
		dfi = "/dfi@ff630000";
		pinctrl = "/pinctrl";
		cif_clkin = "/pinctrl/cif/cif-clkin";
		qos_rga_r = "/qos@ffab0000";
		spi1_tx = "/pinctrl/spi1/spi1-tx";
		dmac_peri = "/dma-controller@ff6e0000";
		vdd_cpu_b = "/i2c@ff3c0000/regulator@40";
		pcie_drv = "/pinctrl/pcie/pcie-drv";
		i2s1 = "/i2s@ff890000";
		hdmi_cec = "/pinctrl/hdmi/hdmi-cec";
		i2c1 = "/i2c@ff110000";
		gpu_leakage = "/efuse@ff690000/gpu-leakage@18";
		gmac = "/ethernet@fe300000";
		qos_usb_otg1 = "/qos@ffa70080";
		spi4_cs0 = "/pinctrl/spi4/spi4-cs0";
		pwm3a_pin = "/pinctrl/pwm3a/pwm3a-pin";
		spi4_rx = "/pinctrl/spi4/spi4-rx";
		vcc5v0_typec_en = "/pinctrl/usb2/vcc5v0-typec-en";
		i2c4_xfer = "/pinctrl/i2c4/i2c4-xfer";
		pcfg_pull_none = "/pinctrl/pcfg-pull-none";
		wifi_host_wake_l = "/pinctrl/wifi/wifi-host-wake-l";
		tcphy1_usb3 = "/phy@ff800000/usb3-port";
		sdmmc0_pwr_h = "/pinctrl/sd/sdmmc0-pwr-h";
		otp_out = "/pinctrl/tsadc/otp-out";
		vopl_out_dp = "/vop@ff8f0000/port/endpoint@4";
		vopl_mmu = "/iommu@ff8f3f00";
		gpu_alert0 = "/thermal-zones/gpu-thermal/trips/gpu_alert0";
		CLUSTER_SLEEP = "/cpus/idle-states/cluster-sleep";
		spi1_rx = "/pinctrl/spi1/spi1-rx";
		typec_ss = "/i2c@ff3d0000/fusb302@22/connector/ports/port@1/endpoint";
		sdhci = "/mmc@fe330000";
		sdmmc_bus1 = "/pinctrl/sdmmc/sdmmc-bus1";
		vcc_sys = "/vcc-sys";
		u2phy1 = "/syscon@ff770000/usb2phy@e460";
		gpu = "/gpu@ff9a0000";
		spi0 = "/spi@ff1c0000";
		iep = "/iep@ff670000";
		isp0 = "/isp0@ff910000";
		pwm0_pin = "/pinctrl/pwm0/pwm0-pin";
		clkin_gmac = "/external-gmac-clock";
		usb_host0_ohci = "/usb@fe3a0000";
		dp_in_vopl = "/dp@fec00000/ports/port/endpoint@1";
		sdio0_cmd = "/pinctrl/sdio0/sdio0-cmd";
		light_int_l = "/pinctrl/cm32181/light-int-l";
		dmc = "/memory-controller";
		qos_isp1_m1 = "/qos@ffaa8080";
		qos_emmc = "/qos@ffa58000";
		edp_in = "/dp@ff970000/ports/port@0";
		vcc3v0_tp = "/i2c@ff3c0000/pmic@1b/regulators/LDO_REG2";
		mipi_dphy_rx0 = "/syscon@ff770000/mipi-dphy-rx0";
		uart3_cts = "/pinctrl/uart3/uart3-cts";
		rmii_pins = "/pinctrl/gmac/rmii-pins";
		pmugrf = "/syscon@ff320000";
		tcphy0_typec_dp = "/phy@ff7c0000/dp-port/port/endpoint";
		sdmmc_wp = "/pinctrl/sdmmc/sdmmc-wp";
		logic_leakage = "/efuse@ff690000/logic-leakage@1b";
		sdio0_bkpwr = "/pinctrl/sdio0/sdio0-bkpwr";
		rktimer = "/rktimer@ff850000";
		vopl = "/vop@ff8f0000";
		qos_pcie = "/qos@ffa60080";
		crypto1 = "/crypto@ff8b8000";
		spi2_clk = "/pinctrl/spi2/spi2-clk";
		i2s0_8ch_bus_bclk_off = "/pinctrl/i2s0/i2s0-8ch-bus-bclk-off";
		gpu_crit = "/thermal-zones/gpu-thermal/trips/gpu_crit";
		vdd_center = "/i2c@ff3c0000/pmic@1b/regulators/DCDC_REG1";
		pcfg_pull_down_18ma = "/pinctrl/pcfg-pull-down-18ma";
		uart4 = "/serial@ff370000";
		uarthdcp_xfer = "/pinctrl/uarthdcp/uarthdcp-xfer";
		u2phy1_host = "/syscon@ff770000/usb2phy@e460/host-port";
		pcie_clkreqnb_cpm = "/pinctrl/pcie/pci-clkreqnb-cpm";
		vdd_gpu = "/i2c@ff3c0000/regulator@41";
		i2c8 = "/i2c@ff3e0000";
		cpu_alert0 = "/thermal-zones/cpu-thermal/trips/cpu_alert0";
		pwr_btn = "/pinctrl/buttons/pwr-btn";
		i2c3_xfer = "/pinctrl/i2c3/i2c3-xfer";
		cpu_thermal = "/thermal-zones/cpu-thermal";
		tcphy0_usb3 = "/phy@ff7c0000/usb3-port";
		power = "/power-management@ff310000/power-controller";
		edp_in_vopl = "/dp@ff970000/ports/port@0/endpoint@1";
		mipi_in = "/dsi@ff960000/ports/port@0";
		vopl_out = "/vop@ff8f0000/port";
		l2_cache_b = "/cpus/l2-cache-cluster1";
		vcc1v8_pmupll = "/i2c@ff3c0000/pmic@1b/regulators/LDO_REG3";
		pwm3 = "/pwm@ff420030";
		tcphy1_dp = "/phy@ff800000/dp-port";
		vbus_typec = "/vbus-typec-regulator";
		vdec_mmu = "/iommu@ff660480";
		sdio0_bus4 = "/pinctrl/sdio0/sdio0-bus4";
		edp_hpd = "/pinctrl/edp/edp-hpd";
		vcc5v0_host = "/vcc5v0-host-regulator";
		cru = "/clock-controller@ff760000";
		phy_rstb = "/pinctrl/gmac/phy-rstb";
		cpu_b1 = "/cpus/cpu@101";
		uart4_xfer = "/pinctrl/uart4/uart4-xfer";
		mipi_dsi1 = "/dsi@ff968000";
		pcfg_pull_down_20ma = "/pinctrl/pcfg-pull-down-20ma";
		uart2 = "/serial@ff1a0000";
		spi1_cs0 = "/pinctrl/spi1/spi1-cs0";
		qos_usb_host0 = "/qos@ffa60100";
		qos_rga_w = "/qos@ffab0080";
		pcfg_output_low = "/pinctrl/pcfg-output-low";
		sdio_pwrseq = "/sdio-pwrseq";
		ppi_cluster0 = "/interrupt-controller@fee00000/ppi-partitions/interrupt-partition-0";
		i2c6 = "/i2c@ff150000";
		vdec = "/video-codec@ff660000";
		sdio0_clk = "/pinctrl/sdio0/sdio0-clk";
		pmu_io_domains = "/syscon@ff320000/io-domains";
		pcfg_pull_none_13ma = "/pinctrl/pcfg-pull-none-13ma";
		spi5_cs0 = "/pinctrl/spi5/spi5-cs0";
		hdmi_i2c_xfer = "/pinctrl/hdmi/hdmi-i2c-xfer";
		gic = "/interrupt-controller@fee00000";
		pcfg_input_pull_down = "/pinctrl/pcfg-input-pull-down";
		phy_intb = "/pinctrl/gmac/phy-intb";
		hdmi_in_vopb = "/hdmi@ff940000/ports/port@0/endpoint@0";
		pcie0 = "/pcie@f8000000";
		pwm3b_pin = "/pinctrl/pwm3b/pwm3b-pin";
		pcfg_pull_down_8ma = "/pinctrl/pcfg-pull-down-8ma";
		efuse0 = "/efuse@ff690000";
		usbdrd3_1 = "/usb@fe900000";
		pwm1 = "/pwm@ff420010";
		vcc3v0_sd = "/vcc3v0-sd";
		cpu_id = "/efuse@ff690000/cpu-id@7";
		vpu = "/video-codec@ff650000";
		edp = "/dp@ff970000";
		usbdrd_dwc3_0 = "/usb@fe800000/usb@fe800000";
		otp_pin = "/pinctrl/tsadc/otp-pin";
		u2phy0_host = "/syscon@ff770000/usb2phy@e450/host-port";
		i2s0_2ch_bus_bclk_off = "/pinctrl/i2s0/i2s0-2ch-bus-bclk-off";
		spi3_tx = "/pinctrl/spi3/spi3-tx";
		usb_host1_ehci = "/usb@fe3c0000";
		xin24m = "/xin24m";
		pcfg_pull_up_2ma = "/pinctrl/pcfg-pull-up-2ma";
		spi5 = "/spi@ff200000";
		tsadc = "/tsadc@ff260000";
		uart0_cts = "/pinctrl/uart0/uart0-cts";
		gpio3 = "/pinctrl/gpio@ff788000";
		pwm1_pin = "/pinctrl/pwm1/pwm1-pin";
		gpu_opp_table = "/opp-table-2";
		pcfg_output_high = "/pinctrl/pcfg-output-high";
		spi0_tx = "/pinctrl/spi0/spi0-tx";
		uart0 = "/serial@ff180000";
		pwm1_pin_pull_down = "/pinctrl/pwm1/pwm1-pin-pull-down";
		ddrio_pwroff = "/pinctrl/suspend/ddrio-pwroff";
		uart3_rts = "/pinctrl/uart3/uart3-rts";
		i2c2_xfer = "/pinctrl/i2c2/i2c2-xfer";
		pmic_int_l = "/pinctrl/pmic/pmic-int-l";
		pcie_phy = "/syscon@ff770000/pcie-phy";
		rk808 = "/i2c@ff3c0000/pmic@1b";
		vcc5v0_host_en = "/pinctrl/usb2/vcc5v0-host-en";
		u2phy0_otg = "/syscon@ff770000/usb2phy@e450/otg-port";
		qos_hdcp = "/qos@ffa90000";
		i2c4 = "/i2c@ff3d0000";
		cpul_leakage = "/efuse@ff690000/cpu-leakage@1a";
		spi3_rx = "/pinctrl/spi3/spi3-rx";
		vcc_1v5 = "/i2c@ff3c0000/pmic@1b/regulators/LDO_REG6";
		isp0_mmu = "/iommu@ff914000";
		typec_con = "/i2c@ff3d0000/fusb302@22/connector";
		spi0_rx = "/pinctrl/spi0/spi0-rx";
		mipi_in_vopl = "/dsi@ff960000/ports/port@0/endpoint@1";
		iep_mmu = "/iommu@ff670800";
		uart3_xfer = "/pinctrl/uart3/uart3-xfer";
		spdif = "/spdif@ff870000";
		vopl_out_edp = "/vop@ff8f0000/port/endpoint@1";
		spi3_clk = "/pinctrl/spi3/spi3-clk";
		i2c8_xfer = "/pinctrl/i2c8/i2c8-xfer";
		sdmmc_cd = "/pinctrl/sdmmc/sdmmc-cd";
		cpu_l2 = "/cpus/cpu@2";
		bt_reg_on_h = "/pinctrl/bluetooth/bt-enable-h";
		sdmmc_bus4 = "/pinctrl/sdmmc/sdmmc-bus4";
		sdio0_wp = "/pinctrl/sdio0/sdio0-wp";
		spi3 = "/spi@ff350000";
		qos_isp0_m1 = "/qos@ffaa0080";
		gpio1 = "/pinctrl/gpio@ff730000";
		test_clkout2 = "/pinctrl/testclk/test-clkout2";
		pcfg_pull_up_18ma = "/pinctrl/pcfg-pull-up-18ma";
		qos_vop_big_r = "/qos@ffac8000";
		spi0_cs1 = "/pinctrl/spi0/spi0-cs1";
		its = "/interrupt-controller@fee00000/msi-controller@fee20000";
		sdio0 = "/mmc@fe310000";
		hdmi_out = "/hdmi@ff940000/ports/port@1";
		i2s2 = "/i2s@ff8a0000";
		rgmii_pins = "/pinctrl/gmac/rgmii-pins";
		i2c2 = "/i2c@ff120000";
		gsensor_int_l = "/pinctrl/mpu6500/gsensor-int-l";
		spdif_bus = "/pinctrl/spdif/spdif-bus";
		vopb_mmu = "/iommu@ff903f00";
		mipi1_in_vopb = "/dsi@ff968000/ports/port@0/endpoint@0";
		pcie0_ep = "/pcie-ep@f8000000";
		sdmmc_pwr = "/pinctrl/sdio0/sdmmc-pwr";
		usb_host0_ehci = "/usb@fe380000";
		i2s1_2ch_bus = "/pinctrl/i2s1/i2s1-2ch-bus";
		vopb_out_mipi1 = "/vop@ff900000/port/endpoint@3";
		qos_vop_little = "/qos@ffad0000";
		tcphy0 = "/phy@ff7c0000";
		vopl_out_mipi1 = "/vop@ff8f0000/port/endpoint@3";
		tcphy0_typec_ss = "/phy@ff7c0000/usb3-port/port/endpoint";
		brcmf = "/mmc@fe310000/wifi@1";
		keys = "/gpio-keys";
		pcfg_pull_up_8ma = "/pinctrl/pcfg-pull-up-8ma";
		i2c1_xfer = "/pinctrl/i2c1/i2c1-xfer";
		vcc_3v0 = "/i2c@ff3c0000/pmic@1b/regulators/LDO_REG8";
		cpu_l0 = "/cpus/cpu@0";
		spi2_cs0 = "/pinctrl/spi2/spi2-cs0";
		pmucru = "/clock-controller@ff750000";
		vdd_log = "/vdd-log";
		pcfg_pull_down_4ma = "/pinctrl/pcfg-pull-down-4ma";
		vcc_ddr = "/i2c@ff3c0000/pmic@1b/regulators/DCDC_REG3";
		spi1 = "/spi@ff1d0000";
		vdd_cpu_l = "/i2c@ff3c0000/pmic@1b/regulators/DCDC_REG2";
		pcfg_pull_up_20ma = "/pinctrl/pcfg-pull-up-20ma";
		isp1 = "/isp1@ff920000";
		test_clkout0 = "/pinctrl/testclk/test-clkout0";
		vopb_out_dp = "/vop@ff900000/port/endpoint@4";
		vcc1v8_s3 = "/vcc1v8-s3";
		rtl8211e = "/ethernet@fe300000/mdio/ethernet-phy@1";
		vop1_pwm_pin = "/pinctrl/pwm0/vop1-pwm-pin";
		qos_video_m1_r = "/qos@ffac0000";
		tcphy0_dp = "/phy@ff7c0000/dp-port";
		sdmmc = "/mmc@fe320000";
		i2s0 = "/i2s@ff880000";
		chg_cc_int_l = "/pinctrl/fusb302/chg-cc-int-l";
		spdif_bus_1 = "/pinctrl/spdif/spdif-bus-1";
		i2c0 = "/i2c@ff3c0000";
		dp_in_vopb = "/dp@fec00000/ports/port/endpoint@0";
		dmac_bus = "/dma-controller@ff6d0000";
		i2c7_xfer = "/pinctrl/i2c7/i2c7-xfer";
		vcc3v3_s0 = "/i2c@ff3c0000/pmic@1b/regulators/SWITCH_REG2";
		uart0_rts = "/pinctrl/uart0/uart0-rts";
		qos_usb_otg0 = "/qos@ffa70000";
		i2s0_8ch_bus = "/pinctrl/i2s0/i2s0-8ch-bus";
		pcfg_pull_none_12ma = "/pinctrl/pcfg-pull-none-12ma";
		uart2c_xfer = "/pinctrl/uart2c/uart2c-xfer";
		vcc_sdio = "/i2c@ff3c0000/pmic@1b/regulators/LDO_REG4";
		io_domains = "/syscon@ff770000/io-domains";
		pwm2_pin = "/pinctrl/pwm2/pwm2-pin";
		vcca3v0_codec = "/i2c@ff3c0000/pmic@1b/regulators/LDO_REG5";
		edp_out = "/dp@ff970000/ports/port@1";
		wafer_info = "/efuse@ff690000/wafer-info@1c";
		wifi_reg_on_h = "/pinctrl/sdio-pwrseq/wifi-reg-on-h";
		pcie0_intc = "/pcie@f8000000/interrupt-controller";
		cif_clkouta = "/pinctrl/cif/cif-clkouta";
		vopb = "/vop@ff900000";
		u2phy0 = "/syscon@ff770000/usb2phy@e450";
		vopb_out_hdmi = "/vop@ff900000/port/endpoint@2";
		u2phy1_otg = "/syscon@ff770000/usb2phy@e460/otg-port";
		vopb_out = "/vop@ff900000/port";
		qos_perihp = "/qos@ffad8080";
		gpu_sleep = "/pinctrl/pmic/gpu-sleep";
		spi0_clk = "/pinctrl/spi0/spi0-clk";
		cpu_alert1 = "/thermal-zones/cpu-thermal/trips/cpu_alert1";
		qos_isp1_m0 = "/qos@ffaa8000";
		spi5_tx = "/pinctrl/spi5/spi5-tx";
		isp1_mmu = "/iommu@ff924000";
		pcfg_input_pull_up = "/pinctrl/pcfg-input-pull-up";
		ap_pwroff = "/pinctrl/suspend/ap-pwroff";
		qos_sdioaudio = "/qos@ffa76000";
		spi2_tx = "/pinctrl/spi2/spi2-tx";
		i2c0_xfer = "/pinctrl/i2c0/i2c0-xfer";
		vcc3v3_sys = "/vcc3v3-sys";
		spi4_clk = "/pinctrl/spi4/spi4-clk";
		edp_in_vopb = "/dp@ff970000/ports/port@0/endpoint@0";
		vcca1v8_s3 = "/vcc1v8-s3";
		typec_dp = "/i2c@ff3d0000/fusb302@22/connector/ports/port@2/endpoint";
		crypto0 = "/crypto@ff8b0000";
		vcca1v8_codec = "/i2c@ff3c0000/pmic@1b/regulators/LDO_REG7";
		spi5_rx = "/pinctrl/spi5/spi5-rx";
		pcfg_pull_down = "/pinctrl/pcfg-pull-down";
		pcfg_input_enable = "/pinctrl/pcfg-input-enable";
		pcie_clkreqn_cpm = "/pinctrl/pcie/pci-clkreqn-cpm";
		uart3 = "/serial@ff1b0000";
		pcfg_pull_up = "/pinctrl/pcfg-pull-up";
		qos_vop_big_w = "/qos@ffac8080";
		vpu_mmu = "/iommu@ff650800";
		qos_usb_host1 = "/qos@ffa60180";
		uart1_xfer = "/pinctrl/uart1/uart1-xfer";
		spi2_rx = "/pinctrl/spi2/spi2-rx";
		sdio0_cd = "/pinctrl/sdio0/sdio0-cd";
		mipi1_out = "/dsi@ff968000/ports/port@1";
		cpub_leakage = "/efuse@ff690000/cpu-leakage@17";
		i2c6_xfer = "/pinctrl/i2c6/i2c6-xfer";
		cluster0_opp = "/opp-table-0";
		ppi_cluster1 = "/interrupt-controller@fee00000/ppi-partitions/interrupt-partition-1";
		i2c7 = "/i2c@ff160000";
		l2_cache_l = "/cpus/l2-cache-cluster0";
		vcc_1v8 = "/i2c@ff3c0000/pmic@1b/regulators/DCDC_REG4";
		gyr_int_l = "/pinctrl/lsm6ds3/gyr-int-l";
		sdmmc_cmd = "/pinctrl/sdmmc/sdmmc-cmd";
		uart2b_xfer = "/pinctrl/uart2b/uart2b-xfer";
		bt_host_wake_l = "/pinctrl/bluetooth/bt-host-wake-l";
		u2phy0_typec_hs = "/syscon@ff770000/usb2phy@e450/port/endpoint";
		qos_gmac = "/qos@ffa5c000";
		vopb_out_edp = "/vop@ff900000/port/endpoint@0";
		vopb_out_mipi = "/vop@ff900000/port/endpoint@1";
		pwm2 = "/pwm@ff420020";
		CPU_SLEEP = "/cpus/idle-states/cpu-sleep";
		pcfg_pull_none_18ma = "/pinctrl/pcfg-pull-none-18ma";
		usbdrd_dwc3_1 = "/usb@fe900000/usb@fe900000";
		spi3_cs0 = "/pinctrl/spi3/spi3-cs0";
		qos_video_m0 = "/qos@ffab8000";
		pmu = "/power-management@ff310000";
		pwm2_pin_pull_down = "/pinctrl/pwm2/pwm2-pin-pull-down";
		bt_wake_l = "/pinctrl/bluetooth/bt-wake-l";
		cpu_b0 = "/cpus/cpu@100";
		gpio4 = "/pinctrl/gpio@ff790000";
		gpu_thermal = "/thermal-zones/gpu-thermal";
		uart1 = "/serial@ff190000";
		hdmi = "/hdmi@ff940000";
		vopl_out_hdmi = "/vop@ff8f0000/port/endpoint@2";
		i2s1_2ch_bus_bclk_off = "/pinctrl/i2s1/i2s1-2ch-bus-bclk-off";
		mipi_out = "/dsi@ff960000/ports/port@1";
		cdn_dp = "/dp@fec00000";
		qos_video_m1_w = "/qos@ffac0080";
		hdmi_in_vopl = "/hdmi@ff940000/ports/port@0/endpoint@1";
		hdmi_in = "/hdmi@ff940000/ports/port@0";
		i2c5 = "/i2c@ff140000";
		mipi_dsi = "/dsi@ff960000";
		sdio0_pwr = "/pinctrl/sdio0/sdio0-pwr";
		grf = "/syscon@ff770000";
		mipi1_in = "/dsi@ff968000/ports/port@0";
		dp_in = "/dp@fec00000/ports/port";
		usbdrd3_0 = "/usb@fe800000";
		pcfg_pull_none_20ma = "/pinctrl/pcfg-pull-none-20ma";
		pwm0 = "/pwm@ff420000";
		qos_sd = "/qos@ffa74000";
		hdmi_sound = "/hdmi-sound";
		cpu_l3 = "/cpus/cpu@3";
		sdio0_bus1 = "/pinctrl/sdio0/sdio0-bus1";
		uart0_xfer = "/pinctrl/uart0/uart0-xfer";
		sdio0_int = "/pinctrl/sdio0/sdio0-int";
		mipi_in_vopb = "/dsi@ff960000/ports/port@0/endpoint@0";
		spi4 = "/spi@ff1f0000";
		i2c5_xfer = "/pinctrl/i2c5/i2c5-xfer";
		gpio2 = "/pinctrl/gpio@ff780000";
		vcc1v8_dvp = "/i2c@ff3c0000/pmic@1b/regulators/LDO_REG1";
		center_leakage = "/efuse@ff690000/center-leakage@19";
		spi1_clk = "/pinctrl/spi1/spi1-clk";
		rga = "/rga@ff680000";
		uart2a_xfer = "/pinctrl/uart2a/uart2a-xfer";
		pwm0_pin_pull_down = "/pinctrl/pwm0/pwm0-pin-pull-down";
		emmc_phy = "/syscon@ff770000/phy@f780";
	};

	i2c@ff3d0000 {
		pinctrl-names = "default";
		#address-cells = <0x01>;
		pinctrl-0 = <0x8f>;
		clock-names = "i2c\0pclk";
		assigned-clocks = <0x84 0x0a>;
		i2c-scl-rising-time-ns = <0x1c2>;
		i2c-scl-falling-time-ns = <0x0f>;
		assigned-clock-rates = <0xbebc200>;
		interrupts = <0x00 0x38 0x04 0x00>;
		clocks = <0x84 0x0a 0x84 0x1c>;
		#size-cells = <0x00>;
		clock-frequency = <0x61a80>;
		compatible = "rockchip,rk3399-i2c";
		status = "okay";
		reg = <0x00 0xff3d0000 0x00 0x1000>;
		phandle = <0x111>;

		lsm6ds3@6a {
			pinctrl-names = "default";
			pinctrl-0 = <0x91>;
			interrupts = <0x18 0x01>;
			interrupt-parent = <0x8b>;
			vdd-supply = <0x1f>;
			compatible = "st,lsm6ds3";
			vddio-supply = <0x1f>;
			reg = <0x6a>;
		};

		cm32181@10 {
			pinctrl-names = "default";
			pinctrl-0 = <0x93>;
			interrupts = <0x18 0x01>;
			interrupt-parent = <0x92>;
			vdd-supply = <0x1f>;
			compatible = "capella,cm32181";
			reg = <0x10>;
		};

		mpu6500@68 {
			pinctrl-names = "default";
			pinctrl-0 = <0x90>;
			interrupts = <0x16 0x01>;
			interrupt-parent = <0x8b>;
			compatible = "invensense,mpu6500";
			vddio-supply = <0x1f>;
			reg = <0x68>;
		};

		ak09911@c {
			vid-supply = <0x1f>;
			vdd-supply = <0x1f>;
			compatible = "asahi-kasei,ak09911";
			reg = <0x0c>;
		};

		fusb302@22 {
			pinctrl-names = "default";
			pinctrl-0 = <0x94>;
			interrupts = <0x02 0x08>;
			vbus-supply = <0x95>;
			interrupt-parent = <0x8b>;
			compatible = "fcs,fusb302";
			reg = <0x22>;

			connector {
				sink-pdos = <0x40190fa>;
				power-role = "dual";
				source-pdos = <0x401908c>;
				data-role = "host";
				label = "USB-C";
				try-power-role = "sink";
				compatible = "usb-c-connector";
				op-sink-microwatt = <0xf4240>;
				phandle = <0x112>;

				ports {
					#address-cells = <0x01>;
					#size-cells = <0x00>;

					port@0 {
						reg = <0x00>;

						endpoint {
							remote-endpoint = <0x96>;
							phandle = <0xa4>;
						};
					};

					port@1 {
						reg = <0x01>;

						endpoint {
							remote-endpoint = <0x97>;
							phandle = <0xa7>;
						};
					};

					port@2 {
						reg = <0x02>;

						endpoint {
							remote-endpoint = <0x98>;
							phandle = <0xa6>;
						};
					};
				};
			};
		};
	};

	qos@ffac0000 {
		compatible = "rockchip,rk3399-qos\0syscon";
		reg = <0x00 0xffac0000 0x00 0x20>;
		phandle = <0x72>;
	};

	debug@fe430000 {
		clock-names = "apb_pclk";
		clocks = <0x08 0x14d>;
		cpu = <0x02>;
		compatible = "arm,coresight-cpu-debug\0arm,primecell";
		reg = <0x00 0xfe430000 0x00 0x1000>;
	};

	qos@ffa60100 {
		compatible = "rockchip,rk3399-qos\0syscon";
		reg = <0x00 0xffa60100 0x00 0x20>;
		phandle = <0x101>;
	};

	qos@ffab8000 {
		compatible = "rockchip,rk3399-qos\0syscon";
		reg = <0x00 0xffab8000 0x00 0x20>;
		phandle = <0x71>;
	};

	debug@fe710000 {
		clock-names = "apb_pclk";
		clocks = <0x08 0x14c>;
		cpu = <0x07>;
		compatible = "arm,coresight-cpu-debug\0arm,primecell";
		reg = <0x00 0xfe710000 0x00 0x1000>;
	};

	clock-controller@ff760000 {
		#reset-cells = <0x01>;
		clock-names = "xin24m";
		assigned-clocks = <0x08 0x05 0x08 0x04 0x08 0x06 0x08 0xc0 0x08 0x1c0 0x08 0x140 0x08 0xc2 0x08 0x1c1 0x08 0x142 0x08 0xc9 0x08 0x1c2 0x08 0x143 0x08 0xe3 0x08 0xde 0x08 0x106 0x08 0x178 0x08 0xed>;
		assigned-clock-rates = <0x2367b880 0x2faf0800 0x3b9aca00 0x8f0d180 0x47868c0 0x23c3460 0x5f5e100 0x5f5e100 0x2faf080 0x23c34600 0x5f5e100 0x2faf080 0x17d78400 0x17d78400 0xbebc200 0xbebc200 0x17d78400>;
		clocks = <0xa1>;
		#clock-cells = <0x01>;
		compatible = "rockchip,rk3399-cru";
		rockchip,grf = <0x1d>;
		reg = <0x00 0xff760000 0x00 0x1000>;
		phandle = <0x08>;
	};

	vop@ff8f0000 {
		power-domains = <0x1c 0x12>;
		iommus = <0xac>;
		clock-names = "aclk_vop\0dclk_vop\0hclk_vop";
		assigned-clocks = <0x08 0xdb 0x08 0x1db>;
		assigned-clock-rates = <0x17d78400 0x5f5e100>;
		resets = <0x08 0x113 0x08 0x117 0x08 0x119>;
		interrupts = <0x00 0x77 0x04 0x00>;
		clocks = <0x08 0xdb 0x08 0xb5 0x08 0x1db>;
		compatible = "rockchip,rk3399-vop-lit";
		status = "okay";
		reg = <0x00 0xff8f0000 0x00 0x2000 0x00 0xff8f2000 0x00 0x400>;
		phandle = <0x12a>;
		reset-names = "axi\0ahb\0dclk";

		port {
			#address-cells = <0x01>;
			#size-cells = <0x00>;
			phandle = <0x11>;

			endpoint@3 {
				remote-endpoint = <0xb0>;
				reg = <0x03>;
				phandle = <0xc4>;
			};

			endpoint@1 {
				remote-endpoint = <0xae>;
				reg = <0x01>;
				phandle = <0xc7>;
			};

			endpoint@4 {
				remote-endpoint = <0xb1>;
				reg = <0x04>;
				phandle = <0x3d>;
			};

			endpoint@2 {
				remote-endpoint = <0xaf>;
				reg = <0x02>;
				phandle = <0xc0>;
			};

			endpoint@0 {
				remote-endpoint = <0xad>;
				reg = <0x00>;
				phandle = <0xc2>;
			};
		};
	};

	qos@ffac8080 {
		compatible = "rockchip,rk3399-qos\0syscon";
		reg = <0x00 0xffac8080 0x00 0x20>;
		phandle = <0x81>;
	};

	serial@ff370000 {
		reg-io-width = <0x04>;
		pinctrl-names = "default";
		pinctrl-0 = <0x89>;
		clock-names = "baudclk\0apb_pclk";
		interrupts = <0x00 0x66 0x04 0x00>;
		clocks = <0x84 0x06 0x84 0x22>;
		compatible = "rockchip,rk3399-uart\0snps,dw-apb-uart";
		status = "disabled";
		reg = <0x00 0xff370000 0x00 0x100>;
		phandle = <0x107>;
		reg-shift = <0x02>;
	};

	spdif@ff870000 {
		power-domains = <0x1c 0x1c>;
		pinctrl-names = "default";
		pinctrl-0 = <0xa8>;
		clock-names = "mclk\0hclk";
		interrupts = <0x00 0x42 0x04 0x00>;
		clocks = <0x08 0x55 0x08 0x1d7>;
		dma-names = "tx";
		#sound-dai-cells = <0x00>;
		compatible = "rockchip,rk3399-spdif";
		status = "disabled";
		reg = <0x00 0xff870000 0x00 0x1000>;
		phandle = <0x127>;
		dmas = <0x62 0x07>;
	};

	vcc-sys {
		regulator-max-microvolt = <0x4c4b40>;
		regulator-boot-on;
		regulator-always-on;
		regulator-min-microvolt = <0x4c4b40>;
		regulator-name = "vcc_sys";
		compatible = "regulator-fixed";
		phandle = <0xd5>;
		vin-supply = <0xd8>;
	};

	i2c@ff110000 {
		pinctrl-names = "default";
		#address-cells = <0x01>;
		pinctrl-0 = <0x3f>;
		clock-names = "i2c\0pclk";
		assigned-clocks = <0x08 0x41>;
		i2c-scl-rising-time-ns = <0x1c2>;
		i2c-scl-falling-time-ns = <0x0f>;
		assigned-clock-rates = <0xbebc200>;
		interrupts = <0x00 0x3b 0x04 0x00>;
		clocks = <0x08 0x41 0x08 0x155>;
		#size-cells = <0x00>;
		compatible = "rockchip,rk3399-i2c";
		status = "okay";
		reg = <0x00 0xff110000 0x00 0x1000>;
		phandle = <0xed>;
	};

	memory {
		device_type = "memory";
		reg = <0x00 0x200000 0x00 0xf7e00000>;
	};

	mmc@fe310000 {
		power-domains = <0x1c 0x1c>;
		fifo-depth = <0x100>;
		pinctrl-names = "default";
		#address-cells = <0x01>;
		pinctrl-0 = <0x26 0x27 0x28>;
		clock-names = "biu\0ciu\0ciu-drive\0ciu-sample";
		cap-sd-highspeed;
		bus-width = <0x04>;
		non-removable;
		resets = <0x08 0x79>;
		cap-sdio-irq;
		interrupts = <0x00 0x40 0x04 0x00>;
		clocks = <0x08 0x1ee 0x08 0x4d 0x08 0x9c 0x08 0x9d>;
		#size-cells = <0x00>;
		keep-power-in-suspend;
		clock-frequency = <0x2faf080>;
		compatible = "rockchip,rk3399-dw-mshc\0rockchip,rk3288-dw-mshc";
		status = "okay";
		disable-wp;
		mmc-pwrseq = <0x25>;
		reg = <0x00 0xfe310000 0x00 0x4000>;
		phandle = <0xde>;
		sd-uhs-sdr104;
		max-frequency = <0x2faf080>;
		reset-names = "reset";

		wifi@1 {
			pinctrl-names = "default";
			pinctrl-0 = <0x2a>;
			interrupts = <0x03 0x04>;
			interrupt-parent = <0x29>;
			compatible = "brcm,bcm4329-fmac";
			interrupt-names = "host-wake";
			reg = <0x01>;
			phandle = <0xdf>;
		};
	};

	pwm@ff420030 {
		pinctrl-names = "default";
		pinctrl-0 = <0x9d>;
		clocks = <0x84 0x1e>;
		#pwm-cells = <0x03>;
		compatible = "rockchip,rk3399-pwm\0rockchip,rk3288-pwm";
		status = "disabled";
		reg = <0x00 0xff420030 0x00 0x10>;
		phandle = <0x116>;
	};

	qos@ffa90000 {
		compatible = "rockchip,rk3399-qos\0syscon";
		reg = <0x00 0xffa90000 0x00 0x20>;
		phandle = <0x7b>;
	};

	qos@ffa60080 {
		compatible = "rockchip,rk3399-qos\0syscon";
		reg = <0x00 0xffa60080 0x00 0x20>;
		phandle = <0x100>;
	};
};
